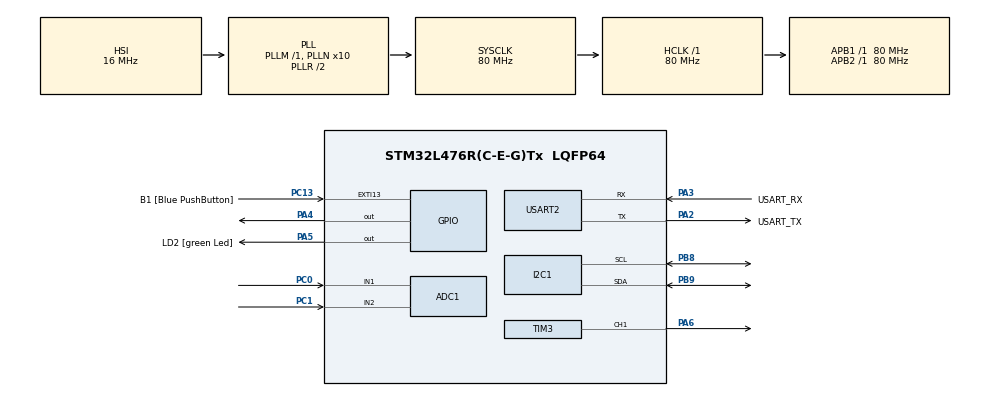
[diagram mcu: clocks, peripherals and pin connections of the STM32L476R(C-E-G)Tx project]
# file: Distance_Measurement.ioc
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ADC1.Channel-0\#ChannelRegularConversion=ADC_CHANNEL_1
ADC1.NbrOfConversionFlag=1
ADC1.OffsetNumber-0\#ChannelRegularConversion=ADC_OFFSET_NONE
ADC1.Rank-0\#ChannelRegularConversion=1
ADC1.SamplingTime-0\#ChannelRegularConversion=ADC_SAMPLETIME_2CYCLES_5
ADC1.master=1
I2C1.Timing=0x10909CEC
Mcu.Family=STM32L4
Mcu.Name=STM32L476R(C-E-G)Tx
Mcu.Package=LQFP64
NVIC.PriorityGroup=NVIC_PRIORITYGROUP_4
PA13\ (JTMS-SWDIO).GPIO_Label=TMS
PA13\ (JTMS-SWDIO).Mode=Serial_Wire
PA13\ (JTMS-SWDIO).Signal=SYS_JTMS-SWDIO
PA14\ (JTCK-SWCLK).GPIO_Label=TCK
PA14\ (JTCK-SWCLK).Mode=Serial_Wire
PA14\ (JTCK-SWCLK).Signal=SYS_JTCK-SWCLK
PA2.GPIO_Label=USART_TX
PA2.GPIO_Mode=GPIO_MODE_AF_PP
PA2.GPIO_PuPd=GPIO_NOPULL
PA2.GPIO_Speed=GPIO_SPEED_FREQ_VERY_HIGH
PA2.Mode=Asynchronous
PA2.Signal=USART2_TX
PA3.GPIO_Label=USART_RX
PA3.GPIO_Mode=GPIO_MODE_AF_PP
PA3.GPIO_PuPd=GPIO_NOPULL
PA3.GPIO_Speed=GPIO_SPEED_FREQ_VERY_HIGH
PA3.Mode=Asynchronous
PA3.Signal=USART2_RX
PA4.Signal=GPIO_Output
PA5.GPIO_Label=LD2 [green Led]
PA5.GPIO_ModeDefaultOutputPP=GPIO_MODE_OUTPUT_PP
PA5.GPIO_PuPd=GPIO_NOPULL
PA5.GPIO_Speed=GPIO_SPEED_FREQ_LOW
PA5.Signal=GPIO_Output
PA6.Signal=S_TIM3_CH1
PB3\ (JTDO-TRACESWO).GPIO_Label=SWO
PB3\ (JTDO-TRACESWO).Signal=SYS_JTDO-SWO
PB8.Mode=I2C
PB8.Signal=I2C1_SCL
PB9.Mode=I2C
PB9.Signal=I2C1_SDA
PC0.Signal=ADCx_IN1
PC1.Signal=ADCx_IN2
PC13.GPIO_Label=B1 [Blue PushButton]
PC13.GPIO_ModeDefaultEXTI=GPIO_MODE_IT_FALLING
PC13.GPIO_PuPd=GPIO_NOPULL
PC13.Signal=GPXTI13
PC14-OSC32_IN\ (PC14).Signal=RCC_OSC32_IN
PC15-OSC32_OUT\ (PC15).Signal=RCC_OSC32_OUT
PH0-OSC_IN\ (PH0).Mode=HSE-External-Oscillator
PH0-OSC_IN\ (PH0).Signal=RCC_OSC_IN
PH1-OSC_OUT\ (PH1).Mode=HSE-External-Oscillator
PH1-OSC_OUT\ (PH1).Signal=RCC_OSC_OUT
ProjectManager.HeapSize=0x200
ProjectManager.StackSize=0x400
ProjectManager.TargetToolchain=STM32CubeIDE
RCC.ADCFreq_Value=64000000
RCC.AHBFreq_Value=80000000
RCC.APB1Freq_Value=80000000
RCC.APB1TimFreq_Value=80000000
RCC.APB2Freq_Value=80000000
RCC.APB2TimFreq_Value=80000000
RCC.CortexFreq_Value=80000000
RCC.HCLKFreq_Value=80000000
RCC.HSE_VALUE=8000000
RCC.HSI_VALUE=16000000
RCC.LSE_VALUE=32768
RCC.MSI_VALUE=4000000
RCC.PLLN=10
RCC.PLLSourceVirtual=RCC_PLLSOURCE_HSI
RCC.PREFETCH_ENABLE=1
RCC.SYSCLKFreq_VALUE=80000000
RCC.SYSCLKSource=RCC_SYSCLKSOURCE_PLLCLK
RCC.USBFreq_Value=64000000
RCC.VCOOutputFreq_Value=160000000
SH.ADCx_IN1.0=ADC1_IN1,IN1-Single-Ended
SH.ADCx_IN2.0=ADC1_IN2,IN2-Single-Ended
SH.S_TIM3_CH1.0=TIM3_CH1,PWM Generation1 CH1
TIM3.AutoReloadPreload=TIM_AUTORELOAD_PRELOAD_ENABLE
TIM3.Channel-PWM\ Generation1\ CH1=TIM_CHANNEL_1
USART2.VirtualMode-Asynchronous=VM_ASYNC
VP_TIM3_VS_ClockSourceINT.Mode=Internal
board=NUCLEO-L476RG

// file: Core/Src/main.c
/* USER CODE BEGIN Header */
/**
  ******************************************************************************
  * @file           : main.c
  * @brief          : Main program body
  ******************************************************************************
  * @attention
  *
  * Copyright (c) 2025 STMicroelectronics.
  * All rights reserved.
  *
  * This software is licensed under terms that can be found in the LICENSE file
  * in the root directory of this software component.
  * If no LICENSE file comes with this software, it is provided AS-IS.
  *
  ******************************************************************************
  */
/* USER CODE END Header */
#include "main.h"

/* USER CODE BEGIN Includes */
#include "stm32l4xx_hal.h"
#include <stdio.h>
#include <stdbool.h>
#include <string.h>
/* USER CODE END Includes */

/* USER CODE BEGIN PD */
#define TMF8801_ADDR ( 0x41 << 1)
#define APPREQID 0x02
#define Bootloader 0x80
#define TMF8x01_OK 0x00  // or whatever the success code is
#define TMF8x01_NK 0x01  // failure or not ready
#define ID 0xE3
#define COMMAND 0x10
#define FACTORY_CALIB 0x0A
#define APPID 0x00
#define DOWNLOAD_CALIB_AND_STATE  0x0B
#define FACTORY_CALIB_0  0x20
#define STATE_DATA_WR_0 0x2E
#define CMD_DATA7 0x08
#define CMD_DATA6 0x09
#define CMD_DATA5 0x0A
#define CMD_DATA4 0x0B
#define CMD_DATA3 0x0C
#define CMD_DATA2 0x0D
#define CMD_DATA1 0x0E
#define CMD_DATA0 0x0F
#define DISTANCE_MEASURE_MODE 0x02
#define STATE_DATA_RD_0  0x2F

/* USER CODE END PD */

ADC_HandleTypeDef hadc1;

I2C_HandleTypeDef hi2c1;

TIM_HandleTypeDef htim3;

UART_HandleTypeDef huart2;

/* USER CODE BEGIN PV */
//uint8_t factory_calib_data[14]={0x41,0x57,0x01,0xFD,0x04,0x00,0x00,0x00,0x00,0x00,0x00,0x00,0x00,0x04};
uint8_t algo_state_data[11]={0xB1,0xA9,0x02,0x00,0x00,0x00,0x00,0x00,0x00,0x00,0x00};
uint8_t factory_calib_data[14];
uint32_t adc_vals[2];
const uint8_t tmf8801_initBuf[] = {
0x10,0x6D,0xC9,0x41,0x85,0x3D,0x15,0xAA,0x51,0xF4,0xD2,0x9E,0xA8,0xA7,0xAC,0x77,0xE9,
0x10,0xF9,0xEC,0x20,0x24,0x63,0xB8,0xF1,0xA5,0x0B,0xA7,0x65,0xB4,0x32,0xB8,0x18,0xD7,
0x10,0x5C,0xF4,0x00,0xD0,0xDC,0xFD,0xD9,0xD5,0x98,0xAF,0x6F,0x40,0x96,0x0A,0xB2,0xFA,
0x10,0x9E,0x13,0x44,0xF8,0x6F,0x5B,0xF1,0x65,0xA6,0x88,0x67,0xD7,0x75,0x0A,0x4A,0x7F,
0x10,0x81,0x9C,0xF6,0x91,0x7B,0xCF,0xF2,0x7C,0x7D,0x84,0xF3,0xA5,0xF6,0xEB,0xD2,0xFA,
0x10,0x59,0x01,0x7B,0x81,0xB2,0xA9,0x31,0x0B,0x8D,0x14,0x9D,0xFE,0xAA,0x24,0x5A,0x5A,
0x10,0x77,0xF0,0x00,0x00,0x88,0x76,0xBA,0x20,0xD1,0x33,0xB2,0x66,0xCF,0xD9,0x37,0xDD,
0x10,0x4C,0xF8,0x5E,0xAD,0x8C,0xF5,0xF4,0x7A,0x60,0x3D,0xFB,0x05,0x4B,0xB9,0x26,0xA5,
0x10,0xDF,0xF1,0xE3,0xC7,0x7E,0x55,0xEC,0x50,0x9C,0xE3,0xC9,0xDA,0x91,0xAE,0x5E,0x9F,
0x10,0x13,0x0E,0x96,0x52,0x27,0x8E,0x06,0x22,0x63,0x69,0xAC,0x61,0x9C,0x23,0xF1,0x38,
0x10,0x5F,0x3A,0x1D,0x03,0xBD,0xCA,0xDA,0x42,0xBB,0x21,0x55,0x35,0xC8,0x30,0x50,0x6D,
0x10,0x09,0xBF,0x32,0x39,0x7D,0xF1,0x4B,0x9C,0x09,0x33,0xF0,0xA1,0xBD,0x1B,0x89,0xCD,
0x10,0xCC,0x75,0x51,0x92,0x52,0x8E,0xA8,0xD1,0xD2,0xED,0x6B,0x63,0x41,0x38,0x0F,0x22,
0x10,0xFF,0xA6,0x6A,0xE3,0xE0,0x78,0x83,0xF5,0x95,0xC2,0x88,0x77,0xE0,0x4B,0x9C,0xAD,
0x10,0x32,0xE4,0x39,0x85,0xBF,0x4E,0x2C,0x21,0xCF,0x19,0x9F,0x93,0xFD,0x9B,0xFA,0x15,
0x10,0x2D,0xB5,0x7C,0xD1,0x43,0x83,0x58,0x4F,0x8C,0x66,0x3E,0xAA,0xD2,0xD2,0x66,0xA1,
0x10,0x56,0x80,0x1A,0xF1,0x65,0x1F,0x4D,0xC5,0x22,0x64,0xB0,0x02,0x7F,0x6A,0x55,0xCE,
0x10,0xA0,0x84,0x62,0x67,0x92,0xE1,0xF9,0x8D,0xE5,0x0F,0x11,0x5B,0x4A,0x4D,0x4A,0xDD,
0x10,0x30,0x5B,0xE7,0x0F,0xDB,0x52,0xD3,0x9A,0xA6,0x0F,0x71,0xD0,0x5C,0x42,0x49,0xFA,
0x10,0xA8,0x9E,0x8B,0x97,0xE2,0x0D,0x13,0xF6,0x92,0x4C,0x97,0xF4,0x29,0x40,0x74,0x44,
0x10,0xE9,0x60,0x0B,0x3F,0xD5,0xD8,0x3B,0x79,0x8F,0x15,0x48,0x82,0x09,0xC5,0x81,0x10,
0x10,0x5B,0xF8,0xE1,0xC7,0x42,0x12,0x1B,0x9A,0x03,0x53,0x41,0x16,0x35,0xC8,0xCB,0x63,
0x10,0xC6,0xB0,0x14,0x84,0xEB,0x29,0x7E,0x5F,0x11,0x41,0x19,0xEF,0xEE,0xD5,0x00,0x8D,
0x10,0xF6,0xC5,0x7C,0x89,0x54,0x24,0xD2,0xBD,0xC1,0xED,0xCE,0x9A,0x88,0xFF,0xE6,0x2D,
0x10,0x57,0x34,0x50,0xCC,0x60,0xC7,0xCF,0x50,0xCC,0x20,0x5B,0x97,0xCC,0x02,0x1B,0x4C,
0x10,0xBF,0x6E,0x1F,0x86,0xC2,0xFB,0x07,0x83,0xCA,0xDE,0x08,0x3A,0xF4,0x99,0xE1,0x3C,
0x10,0x79,0xF5,0xCC,0xFA,0x8F,0x19,0xC8,0x39,0x0F,0x5E,0x7B,0xFA,0x9A,0x99,0xAD,0x7E,
0x10,0x17,0x74,0xF1,0x0C,0x1D,0x8F,0xD8,0x05,0x4A,0xA3,0x06,0x22,0xA8,0x83,0x77,0xDE,
0x10,0x51,0x77,0x4B,0x74,0xD0,0x12,0x60,0x87,0x45,0x61,0xF5,0xBA,0xBD,0x41,0x9B,0x1B,
0x10,0xE5,0xB5,0xFC,0xA9,0x98,0xFC,0x6F,0x29,0x71,0xBB,0x19,0x6E,0xB4,0xC3,0x40,0x28,
0x10,0xB7,0xC7,0x61,0x4D,0xA3,0xB1,0x27,0x3C,0x7F,0x12,0x68,0x69,0xD7,0xF4,0x87,0x1C,
0x10,0x7F,0x41,0x6B,0x3A,0xF8,0x5E,0x95,0x03,0xA5,0x4E,0xB2,0x70,0x4A,0xEC,0xC1,0x10,
0x10,0xE6,0x72,0x1B,0xA7,0x31,0xD1,0x92,0x3C,0x96,0x87,0x7F,0xCF,0x76,0x8A,0xC4,0xDC,
0x10,0x5F,0x69,0x92,0xAE,0xA9,0xF5,0x63,0x9A,0xC4,0x67,0xBA,0x15,0x0B,0xB7,0x76,0xF3,
0x10,0x56,0x65,0x37,0x41,0x85,0x3D,0x85,0xA1,0xC0,0x24,0x09,0x90,0x66,0xFF,0x0B,0xE8,
0x10,0xBD,0x54,0xEF,0x83,0xBE,0xB0,0x6D,0xB8,0xDE,0x30,0x3B,0xF8,0x9A,0xC1,0x1C,0x7F,
0x10,0x2E,0x72,0xC2,0xD7,0xBC,0xD7,0xCA,0xAF,0x97,0x7D,0x5F,0x59,0x68,0x57,0x0B,0x78,
0x10,0x8F,0xD2,0x63,0xC4,0x94,0x3B,0x26,0x4A,0xB9,0x60,0x08,0x69,0x88,0x66,0x91,0xC3,
0x10,0x5C,0xD7,0x77,0xFD,0x46,0x1D,0x3A,0xB3,0x76,0xF7,0x63,0x5E,0x1C,0x84,0x66,0x87,
0x10,0x44,0xFF,0x66,0x07,0xFC,0x51,0xCE,0xAE,0xB8,0xE8,0x44,0x51,0x0D,0x6C,0x79,0xC0,
0x10,0xFC,0xDF,0x57,0x8D,0xDF,0xF4,0x90,0xF5,0xD5,0x01,0xA2,0x1F,0x05,0x70,0x26,0x2F,
0x10,0x30,0xCE,0x07,0x06,0x00,0x57,0xFD,0xCB,0x40,0xA6,0xA8,0xCA,0xE7,0xE0,0x38,0x2F,
0x10,0xC8,0xB7,0x04,0x30,0xBB,0x9D,0x24,0xDB,0x8E,0x8D,0xA4,0xDC,0x9D,0xFB,0xE6,0x51,
0x10,0x5E,0xB7,0x46,0x23,0x57,0x2D,0x76,0x4D,0x0B,0x85,0x04,0x56,0xA0,0x1F,0x3C,0x17,
0x10,0xFB,0x8D,0x9C,0xBF,0x5A,0xEC,0x5A,0x07,0x22,0x7F,0x97,0x6D,0x2B,0xE4,0x5A,0x78,
0x10,0x34,0x3D,0xC1,0xFB,0x60,0xE7,0xF2,0x3C,0x79,0xF0,0x6D,0xB2,0xB7,0x53,0x7B,0x15,
0x10,0x04,0x2F,0x91,0x58,0x05,0x27,0x51,0x42,0x17,0xC3,0x77,0x38,0xEB,0xED,0x65,0x3C,
0x10,0xDF,0x74,0xCE,0xC4,0x1C,0x75,0x9E,0x2D,0x2D,0x19,0xF3,0xB3,0x3A,0x88,0x27,0x25,
0x10,0x28,0xCB,0x58,0xCF,0xCB,0xD8,0xBD,0x89,0xFF,0x04,0xE9,0xB4,0x71,0x12,0xD1,0x3C,
0x10,0xA5,0x79,0xD3,0xCA,0x9C,0xF6,0x3A,0x9C,0xA8,0xE4,0xC2,0x7F,0x3A,0xFB,0xA0,0xCD,
0x10,0xAC,0x8B,0xB3,0xAB,0xAA,0x67,0x70,0xE6,0xD6,0x7B,0x07,0x8F,0xED,0x75,0xA6,0xC9,
0x10,0x96,0xBB,0x74,0xEC,0x3C,0x62,0xC1,0x84,0xF7,0x08,0x1A,0xE4,0x12,0x12,0x46,0x00,
0x10,0xE7,0xB4,0xC9,0xD5,0xF2,0xBD,0x2E,0xED,0x1E,0x1D,0xCC,0xB0,0x01,0xEB,0x10,0xC2,
0x10,0x43,0xBB,0xDD,0x20,0xEB,0xC0,0x4B,0x6F,0x0D,0x38,0x6C,0x6D,0x57,0xDA,0x94,0xCE,
0x10,0x87,0xEE,0x37,0x07,0x7E,0x11,0x7F,0x23,0x0B,0x14,0x56,0x1F,0xB6,0xAC,0xF8,0x2F,
0x10,0x10,0xA7,0x55,0xD7,0xB6,0x76,0x60,0x26,0xD7,0xD9,0x05,0x5C,0xEB,0x3C,0xB3,0x9A,
0x10,0x73,0x70,0xE9,0xCF,0x3F,0x67,0xC7,0x80,0x03,0x4A,0xF3,0x40,0x7F,0x40,0x9C,0x45,
0x10,0x7A,0x43,0x94,0x5F,0xA3,0x14,0x7E,0x01,0x90,0x70,0xD1,0xCB,0xEA,0x08,0xE9,0x8A,
0x10,0x53,0x7C,0x4B,0x3E,0xEC,0xE7,0x68,0x47,0x03,0x85,0xD8,0x92,0x49,0x97,0x08,0xD7,
0x10,0xDB,0x98,0x90,0xF3,0xB8,0x74,0xF2,0xB7,0x7F,0x12,0xF8,0x90,0x2F,0x81,0xCC,0xF2,
0x10,0x7F,0x81,0x88,0xC4,0xC7,0xA2,0x4F,0xA5,0x88,0xF5,0x27,0x36,0x33,0x92,0xBC,0x6C,
0x10,0xA2,0x38,0x55,0x95,0xAE,0x50,0x1E,0xEA,0x2B,0xDA,0x0B,0xED,0x2E,0xF1,0xC1,0x74,
0x10,0x0A,0x99,0x24,0xD4,0x05,0xA9,0xC5,0xB7,0xD8,0x2D,0xD9,0x43,0x5C,0x75,0x2B,0x4C,
0x10,0x39,0x26,0xCE,0x68,0x55,0xBF,0xE4,0xEB,0x11,0xC1,0x96,0xD1,0x91,0xA5,0x82,0x39,
0x10,0x2E,0xFE,0xB2,0x05,0x47,0x56,0x64,0x57,0xCE,0x58,0x55,0x69,0xB1,0x6A,0xF1,0xC1,
0x10,0xC4,0x6D,0x21,0x77,0x38,0xC6,0xEF,0xC3,0x62,0xED,0x00,0x0B,0x74,0xFE,0xC0,0x3F,
0x10,0x4C,0x84,0x13,0x40,0xC0,0xCB,0x14,0x26,0x36,0x9B,0x54,0x21,0xF6,0x7B,0x4E,0x46,
0x10,0xC1,0x1F,0x98,0x22,0xF3,0xF1,0xA2,0x54,0xF9,0x71,0x8E,0xD5,0x1B,0x7A,0xBD,0x51,
0x10,0x7B,0x58,0xAD,0x0D,0x53,0x16,0xD8,0xFA,0xF7,0xB0,0xD0,0x73,0x2A,0x33,0x8F,0x9F,
0x10,0x48,0xA1,0x53,0x0C,0x27,0xCB,0x51,0xE6,0x48,0x1E,0xBB,0x7D,0x7F,0xB7,0x8F,0xF7,
0x10,0x7B,0x94,0xB8,0xBE,0xC6,0x07,0xD8,0xAE,0xBD,0x1B,0xC0,0x3C,0x71,0xBA,0xD0,0x6E,
0x10,0xF3,0x21,0xF4,0x0A,0xE1,0xE2,0xA4,0x41,0x43,0x0B,0xEB,0x80,0x49,0x9C,0xB0,0xC0,
0x10,0xC3,0x94,0x29,0x64,0xF2,0xC3,0x10,0x90,0xF3,0x22,0xD5,0x20,0x04,0x54,0x6E,0x05,
0x10,0x72,0xBE,0x78,0xDD,0x7A,0xBB,0xEC,0xE1,0xC1,0x88,0x7A,0x28,0x57,0x44,0x94,0x63,
0x10,0x19,0x6A,0x2E,0xD8,0x93,0xE5,0x52,0x4F,0xC8,0xD4,0xA8,0xDA,0x11,0x0C,0x85,0xAD,
0x10,0x20,0xBB,0x36,0x45,0x2D,0xDB,0x54,0xD5,0x5A,0xCF,0x93,0xA5,0x12,0x8F,0xE1,0x15,
0x10,0x09,0xBC,0x3F,0xDC,0x21,0xFE,0xF5,0xC8,0x5A,0x42,0x89,0x78,0xFB,0xF2,0x9B,0xB6,
0x10,0x81,0x3F,0x10,0xFB,0x80,0x36,0x58,0x57,0xC6,0xBF,0x43,0x31,0x08,0x81,0x08,0xD8,
0x10,0xF4,0x9B,0x10,0xD8,0xDB,0x45,0xD0,0x97,0x40,0xFD,0xB7,0x5A,0x9E,0x83,0xBF,0xCC,
0x10,0xAC,0x45,0xDB,0xD4,0x8F,0x39,0xD9,0x1A,0x75,0x69,0x8A,0x09,0x23,0x87,0xF7,0x6D,
0x10,0x3E,0xF6,0xDE,0x59,0x51,0x2F,0x94,0xC3,0x7E,0x13,0x2B,0x82,0x16,0x16,0x6F,0x9A,
0x10,0x4B,0xD9,0x05,0xB1,0xCC,0x0E,0x4B,0x70,0xAE,0x9B,0x9F,0xFC,0xC7,0x7B,0x9A,0x0D,
0x10,0xF2,0x0D,0x72,0x1D,0xF2,0x02,0xA8,0x51,0x27,0xAB,0x05,0x96,0xC0,0x31,0x7E,0xF0,
0x10,0x1D,0x5C,0xA3,0x82,0x2C,0x7A,0x65,0xFF,0xDA,0x79,0xB0,0x4A,0xA2,0x3C,0xD2,0xE7,
0x10,0xC5,0x7F,0x58,0x54,0xB8,0x05,0x25,0x40,0x22,0x84,0xA7,0x18,0x4A,0xCA,0x03,0x33,
0x10,0xC9,0x82,0xB5,0xD6,0x55,0x59,0x42,0x6E,0xE4,0x75,0x20,0xFC,0x53,0x1B,0x49,0xFD,
0x10,0xD7,0x56,0x59,0x07,0x90,0xC5,0xE1,0xA7,0x9F,0xAB,0x7F,0x86,0xF8,0x80,0xDC,0xAE,
0x10,0xD9,0x6C,0x79,0x5B,0x4D,0xE4,0x7D,0xB4,0x00,0xEB,0x71,0xD6,0x0D,0x5E,0x20,0xBB,
0x10,0xD2,0xAD,0xA6,0x10,0x50,0x6D,0x5F,0x70,0x30,0x80,0xD8,0xFB,0x41,0x9E,0xF2,0x15,
0x10,0x59,0xC7,0x79,0xB8,0xD1,0xB5,0x51,0xF9,0x4F,0xCC,0x82,0x40,0xBF,0xBC,0x07,0xE6,
0x10,0x32,0x53,0x75,0x66,0x76,0x26,0x5A,0xE4,0x5C,0xCA,0x10,0x70,0x9D,0x39,0xEA,0x80,
0x10,0xF1,0x0E,0x44,0xA3,0xFB,0xC0,0x70,0x5F,0x14,0x7F,0x68,0x35,0xA9,0xD7,0xC3,0x1A,
0x10,0x64,0x1B,0xF9,0x6A,0x96,0xBC,0x9D,0x6A,0xE3,0xFB,0xEC,0x2C,0x56,0xA3,0x5C,0x77,
0x10,0x06,0x52,0x99,0x1A,0xE0,0x28,0xDC,0x57,0x85,0x36,0x97,0xA9,0x27,0xA9,0x65,0x24,
0x10,0xA5,0x2A,0x41,0x0A,0xE2,0xFE,0x29,0x0A,0x2B,0xF0,0xD6,0xF6,0x11,0x33,0x82,0xFE,
0x10,0xE2,0x0F,0xDE,0x77,0x7E,0x7F,0xBC,0xC7,0xA1,0x78,0xAE,0x04,0x19,0x14,0x64,0x94,
0x10,0x17,0x2A,0x46,0x01,0x7F,0xAA,0x98,0xB9,0xAB,0x60,0x2E,0x38,0x7F,0x1A,0xDE,0xA8,
0x10,0x83,0x85,0xD8,0x8D,0xED,0x12,0xED,0x3D,0xC9,0x61,0x71,0xFC,0xEE,0x63,0xE8,0x59,
0x10,0x16,0x79,0x0A,0xA5,0x2D,0xDD,0xF0,0xE7,0x1D,0x90,0x4E,0x2B,0x63,0x7C,0x44,0x4A,
0x10,0x00,0x49,0xBF,0xBD,0xB2,0x05,0x15,0x9D,0xEB,0x63,0x72,0xC1,0xE6,0x60,0x41,0x6F,
0x10,0x53,0xBB,0x9C,0x61,0xCA,0x28,0x96,0x0B,0x05,0x24,0x49,0xFA,0xFF,0xA6,0xEC,0x73,
0x10,0x92,0x39,0xFD,0xEF,0xEA,0xF3,0xA8,0xC0,0x8E,0x33,0xE1,0x4D,0xF3,0x91,0x0C,0xF9,
0x10,0x0A,0x01,0xCC,0xE5,0x35,0x52,0x22,0x90,0xB7,0xF0,0x3F,0x70,0x80,0x85,0x61,0xC8,
0x10,0x17,0xC8,0x14,0x87,0x93,0x9C,0x6B,0x7B,0x71,0x97,0x2F,0x17,0x06,0x4C,0x77,0x90,
0x10,0x18,0xE1,0xA4,0xD0,0x92,0x8E,0x7A,0x88,0x8F,0xB1,0x85,0x55,0x53,0xA5,0xE0,0x59,
0x10,0x49,0xED,0x7C,0xAA,0xBD,0xD6,0x56,0xE5,0xE8,0x9C,0x84,0xC1,0x92,0x66,0xE7,0x36,
0x10,0xCA,0xE3,0x10,0x8C,0xF4,0x6A,0x98,0xE7,0xE4,0x65,0xA1,0x5A,0xB0,0x57,0x18,0x45,
0x10,0x81,0x6A,0x97,0x93,0x5A,0x06,0x05,0x05,0xE6,0x18,0xEC,0x5B,0xF8,0x3B,0x18,0x4A,
0x10,0xB2,0x0E,0x38,0x46,0x73,0xBC,0x3D,0xAE,0xE5,0xB9,0xA1,0x90,0x72,0x52,0xB8,0xDA,
0x10,0x98,0x77,0x30,0x4E,0x81,0xDD,0xE4,0xC3,0xE6,0xB7,0xBF,0x4E,0xE1,0x19,0x07,0xB8,
0x10,0x77,0xF8,0x42,0xDA,0x0F,0x30,0x25,0x7D,0x51,0xC9,0x39,0x01,0x43,0xA3,0xBD,0x6A,
0x10,0xA6,0x73,0x85,0x29,0x7B,0xA8,0x90,0xC0,0x88,0x7A,0xCA,0xE4,0xD5,0xA3,0xFE,0x5B,
0x10,0xFC,0x0B,0xAD,0x13,0xAD,0x72,0xF4,0xF7,0xF4,0x78,0xA0,0xBE,0x64,0x47,0xEE,0xB4,
0x10,0x75,0x8E,0x49,0xB8,0x7C,0xC2,0x6C,0xAC,0xE6,0xAC,0x4D,0xD1,0x01,0x6E,0x41,0x94,
0x10,0xD6,0x63,0x25,0x5A,0x2B,0xF9,0x7D,0xBA,0xCA,0x2D,0x61,0x07,0x8C,0x04,0x40,0x8A,
0x10,0x34,0xB3,0x1C,0x42,0x5C,0x3D,0x06,0x57,0xE5,0xFF,0xE0,0x10,0x5A,0xB3,0x56,0x98,
0x10,0xEC,0xDF,0x8A,0xFB,0xBF,0xB6,0x99,0xFD,0xE0,0xC2,0x73,0x8B,0xE2,0x10,0xE9,0xBF,
0x10,0x7B,0x90,0x18,0x9C,0x6C,0xDE,0x3A,0x3E,0xBE,0xE7,0x80,0xCA,0xF6,0x36,0xE9,0x19,
0x10,0x06,0x3E,0xC5,0x9A,0xC1,0x79,0x72,0x0C,0xF9,0xCE,0x3A,0x5F,0x85,0xDA,0xC2,0x1C,
0x10,0x0B,0x8E,0xF7,0x66,0x7E,0xDC,0x52,0x67,0xB0,0x5F,0x12,0xF0,0x3D,0xE2,0xDD,0x8A,
0x10,0x63,0xDC,0xB6,0x5E,0x02,0x15,0xBB,0x87,0x70,0x52,0xB8,0x2E,0x7B,0xF3,0xA5,0x2F,
0x10,0x78,0xC5,0xD1,0x94,0x97,0x11,0xAE,0xD9,0x46,0x7C,0x1A,0xE3,0xFD,0x63,0x3A,0x14,
0x10,0x96,0xF6,0x59,0x40,0x29,0x9B,0xC3,0x1B,0x96,0x20,0x56,0x30,0x41,0x98,0xEF,0x3F,
0x10,0xB7,0x5A,0x91,0x79,0xD5,0x54,0x97,0x9C,0x99,0x2E,0x49,0x1E,0xA7,0x9C,0xEF,0x7D,
0x10,0xF0,0xB8,0xE5,0x9F,0xC2,0x56,0xE5,0xAA,0xA5,0x9C,0x3E,0x29,0xF8,0xEA,0x5A,0x05,
0x10,0xD9,0x66,0x6D,0xA0,0xF5,0x32,0xB1,0x98,0xCD,0x24,0xCA,0xB7,0x50,0x89,0x2C,0x68,
0x10,0xB9,0xD2,0x55,0x2F,0x76,0x97,0xDC,0xB5,0x64,0x8E,0x5D,0x4F,0xC7,0xCA,0xAD,0x8E,
0x10,0xF9,0xF7,0xE1,0x37,0x48,0xD5,0xD4,0xA7,0x28,0x88,0x63,0x8C,0x72,0x29,0x25,0xEF,
0x10,0x8E,0x49,0x7F,0x80,0x83,0x11,0x62,0x6F,0x5A,0xE8,0x23,0x7B,0x44,0xB8,0xB6,0xBC,
0x10,0x71,0xB4,0x37,0x52,0xD4,0xAF,0x8C,0x5D,0x8A,0xEF,0x1C,0x4F,0x15,0xBB,0xDC,0xEC,
0x10,0x45,0xE2,0x48,0x04,0x59,0x39,0xD1,0xE6,0xF5,0xD6,0x17,0x0D,0x12,0xEB,0xB5,0xA3,
0x10,0xCF,0x25,0x1C,0xFB,0x40,0x72,0x2B,0xE8,0x58,0xF0,0xC0,0x66,0xD7,0x3F,0x3D,0x34,
0x10,0xBA,0xC4,0xE2,0xBE,0x40,0x92,0x7C,0x0D,0x79,0x73,0xBA,0x7C,0x57,0xB9,0xE8,0xC4,
0x10,0x3E,0xCF,0xDF,0x43,0x71,0xD3,0x77,0xBF,0xF2,0xD5,0x73,0xF6,0x3E,0xFA,0x00,0xB0,
0x10,0x77,0x2D,0xAA,0xDF,0xF7,0x61,0xE2,0xE9,0xE0,0x1E,0xA6,0x1E,0xEE,0x5F,0xE6,0x5A,
0x10,0x86,0x18,0x25,0x05,0x9B,0xA3,0x96,0xA8,0xD8,0x59,0xEB,0xAB,0x0D,0xD1,0xE1,0x6A,
0x10,0xB9,0xEC,0x7D,0x5F,0x02,0x70,0x6E,0x0C,0xCB,0x25,0x5C,0x5D,0x68,0xE3,0x4B,0xFE,
0x10,0xA7,0x3C,0x51,0xE2,0xD2,0x77,0x44,0xDA,0xDC,0x24,0x20,0x2F,0x7B,0xC0,0xE3,0x63,
0x10,0x72,0x6B,0xF2,0x1F,0x4B,0x59,0xFF,0x0D,0xFB,0x69,0xF8,0x1F,0xC1,0xF8,0x4D,0x21,
0x10,0xFF,0x6B,0x28,0x60,0x72,0x32,0x08,0xD0,0x1D,0xF8,0xDF,0x25,0x5C,0x05,0xEE,0x39,
0x10,0xEB,0x7E,0xF4,0xBA,0xFA,0xD0,0x83,0x6A,0x81,0x5E,0x53,0x25,0xE1,0x6F,0x3B,0xB7,
0x10,0xA5,0x77,0x5B,0x5C,0x43,0x8E,0xD2,0xC7,0x39,0x84,0x00,0x6D,0xA8,0x0C,0x1C,0xB9,
0x10,0x79,0xDF,0xEE,0xBD,0xC8,0xFA,0xAC,0x6B,0xE3,0x3F,0x4B,0xFB,0x61,0x09,0x04,0x14,
0x10,0x25,0x74,0xA2,0xC4,0xF2,0x42,0x30,0x4C,0x41,0x03,0x91,0x05,0x87,0xD4,0x19,0xA6,
0x10,0xB5,0x17,0x14,0x9E,0xAD,0x62,0xC3,0x46,0x17,0x9A,0x3A,0x9A,0x59,0xC4,0x81,0x25,
0x10,0xB5,0x86,0x82,0x54,0xEA,0x34,0x22,0x88,0x78,0x7D,0xF0,0xDF,0x1D,0x1C,0x78,0xF5,
0x10,0xB6,0x47,0x0E,0x5C,0x21,0x2D,0x41,0xFA,0x61,0x38,0xBD,0xC5,0xE6,0x3B,0xB4,0x60,
0x10,0x1B,0xD7,0xC2,0x0A,0xFE,0x5A,0x1A,0x58,0xBC,0x36,0x6A,0x93,0x2D,0xB1,0xA6,0xA8,
0x10,0xB1,0x7C,0x80,0x28,0xA5,0xF4,0x3A,0x00,0x9A,0x0B,0x80,0x78,0x86,0x96,0x4F,0xDE,
0x10,0xAE,0xF4,0xF6,0x7B,0x41,0x99,0x49,0xC6,0x65,0xC6,0x65,0x7E,0x10,0x22,0x3A,0x54,
0x10,0x0B,0xFD,0x62,0x90,0xC1,0xFE,0x76,0xDF,0x61,0x1F,0x94,0x53,0xB8,0x5A,0xDE,0x9A,
0x10,0x5E,0x2E,0xA2,0x06,0x96,0x5F,0x9C,0xAA,0x27,0x08,0x7A,0x98,0xAD,0x08,0xF0,0xE1,
0x10,0xE1,0xF9,0xDD,0x7C,0xD6,0x7A,0x58,0x91,0xCD,0x62,0x3E,0x8C,0xF2,0xCA,0x05,0x29,
0x10,0x29,0x5D,0x14,0xDD,0xA9,0x2A,0xD2,0x39,0x17,0xA2,0x42,0x69,0x72,0x93,0x51,0x88,
0x10,0x17,0x51,0x7D,0xC6,0x3A,0xD9,0x44,0xF7,0x48,0x63,0xD6,0xCE,0x17,0xFA,0x50,0x7C,
0x10,0x72,0xC1,0xC8,0xD1,0x70,0x5A,0x0E,0x6A,0x0C,0xE2,0xBD,0x96,0xFF,0xEA,0xAF,0xEF,
0x10,0xDF,0x74,0x57,0x35,0x33,0x46,0xA9,0x8B,0x1F,0x02,0x05,0x99,0x76,0x15,0xBA,0x46,
0x10,0xD8,0xDA,0x51,0xA5,0x21,0x92,0x5A,0x47,0x5A,0x2F,0xDA,0x2B,0x82,0x82,0x53,0x11,
0x10,0x93,0xC2,0x50,0x61,0xEC,0x41,0x92,0x84,0xFD,0x63,0x4A,0xA2,0xD8,0x20,0x31,0xCD,
0x10,0xB9,0xB3,0x67,0xD6,0x7A,0xA1,0x13,0x91,0x53,0x4F,0xED,0xF0,0x4B,0x34,0x6C,0x85,
0x10,0x9C,0x54,0xFB,0xE7,0xE8,0x37,0x14,0x2B,0x75,0x9D,0xFA,0xFA,0x35,0x33,0xDE,0x40,
0x10,0xA5,0x3E,0xDB,0xC8,0x5C,0x11,0xEF,0x5C,0xAE,0xDE,0x4C,0xAD,0x9D,0x65,0x48,0x92,
0x10,0x96,0x9F,0x2A,0xA2,0xF9,0x23,0xD6,0x3A,0xD0,0x39,0xEE,0x9D,0xEF,0xA9,0x75,0xAC,
0x10,0xAF,0xC1,0x11,0xCB,0x3F,0xED,0x8C,0x9D,0xAA,0x42,0x28,0xF4,0xC4,0x04,0x52,0x5E,
0x10,0x1E,0x7A,0x6F,0xAA,0xA3,0x78,0xF1,0x8D,0x5A,0x5A,0x76,0x78,0xCE,0x2E,0x5C,0x95,
0x10,0x5A,0x1A,0x0D,0x6B,0x5B,0x15,0x43,0xA3,0x15,0xC2,0x1E,0x43,0xD5,0x7F,0xA9,0xB5,
0x10,0x6F,0xCC,0xB1,0xE7,0x44,0x56,0xED,0x00,0x63,0x43,0x0C,0xF3,0x6A,0xFC,0xE3,0x77,
0x10,0x57,0xEE,0xF9,0x0C,0xB3,0x13,0x64,0x7B,0x26,0xBA,0xCD,0x13,0x3B,0xAE,0x14,0xEC,
0x10,0x89,0x34,0x75,0xAB,0x3E,0x0F,0x32,0x0F,0xDD,0x06,0x05,0x04,0x1A,0xA8,0xEA,0xB4,
0x10,0x6D,0xB4,0x31,0x23,0x12,0x09,0x69,0x8A,0x76,0x90,0x48,0x37,0xF7,0x60,0xF9,0x8D,
0x10,0x84,0x8C,0x74,0xEF,0xAB,0x07,0xF7,0x0F,0x60,0x4F,0xDD,0x09,0x41,0xA2,0xF5,0x6E,
0x10,0xBF,0x8D,0xDA,0xE3,0x85,0x88,0x49,0xD2,0x80,0x02,0x07,0x93,0xE6,0x91,0xC9,0xAA,
0x10,0x1F,0x8D,0x36,0x42,0x37,0xF8,0x2A,0x3B,0x0F,0x25,0x0B,0x09,0x62,0x13,0xF5,0xEE,
0x10,0x1A,0x28,0xC3,0x47,0xBC,0x8D,0xC5,0x6E,0x7B,0xD2,0x0D,0xDB,0xB9,0xB2,0xB4,0xB1,
0x10,0x7F,0x1E,0x42,0xE7,0x39,0xAC,0xEA,0xA6,0x43,0x10,0xCD,0xF2,0xA3,0xFE,0xCE,0x11,
0x10,0x31,0x2F,0xF0,0x09,0x96,0x27,0x70,0x17,0xAC,0xA3,0x77,0xF6,0xE1,0xFE,0xE7,0xB3,
0x10,0x7B,0xD1,0x54,0xBC,0x44,0x89,0x4A,0xF9,0x98,0x3D,0x38,0xCC,0xC2,0xB2,0xFF,0x66,
0x10,0x5F,0xEF,0x55,0xB6,0x5F,0x07,0xB1,0xDF,0x7C,0x06,0x36,0x03,0xFA,0xC3,0xFC,0x85,
0x10,0x5B,0x0A,0x35,0x27,0x23,0xBE,0x93,0x09,0x4A,0xC4,0x3E,0x47,0xF5,0x52,0x99,0x4D,
0x10,0x34,0xB2,0x2E,0x75,0x94,0x19,0x26,0x47,0xE1,0xE3,0x08,0xC4,0xC1,0xF0,0x23,0x4B,
0x10,0x60,0x0D,0xF1,0xB6,0x75,0x03,0x56,0x10,0x20,0xF4,0x1E,0x0B,0x82,0xA5,0x17,0x22,
0x10,0xB9,0x53,0xEA,0x26,0x49,0x84,0xC5,0xFC,0x0E,0xEC,0xFF,0x0B,0xED,0xA7,0x3C,0x25,
0x10,0x9C,0x36,0x90,0xAA,0x7F,0x49,0x28,0x8D,0x4D,0xA0,0xF4,0xF9,0x0A,0xF1,0x0D,0x4A,
0x10,0x7B,0x8C,0x3F,0x2D,0xCE,0x1A,0xA1,0x9E,0x00,0x12,0x07,0xB1,0x60,0xB9,0x74,0xF6,
0x10,0xE1,0x51,0xE3,0x0A,0x9D,0xB7,0x7F,0xE0,0xFF,0xFA,0x05,0x3C,0xBD,0x2C,0x0C,0xDF,
0x10,0xFF,0xA4,0x25,0xF4,0x23,0x2F,0x8E,0x1D,0xF8,0xD0,0x49,0x56,0x54,0xD4,0x6B,0xCA,
0x10,0xF5,0x1C,0xFF,0xAB,0x0E,0x60,0x94,0x93,0x5B,0xFE,0xDB,0x01,0x5C,0x68,0x52,0x27,
0x10,0xE8,0x3A,0x50,0xB0,0x6F,0xDB,0x70,0x5E,0xC8,0xB0,0x94,0x29,0x66,0xF1,0xDD,0x34,
0x10,0x53,0xCD,0xE0,0xC7,0x3D,0xF1,0x9D,0xDC,0x09,0x71,0x7C,0xBF,0x5C,0x44,0x9F,0x72,
0x10,0x4B,0xE9,0xC8,0x9D,0x17,0xF4,0x2F,0x06,0x04,0xEB,0x06,0x86,0x17,0x72,0x69,0xF6,
0x10,0x3B,0xC2,0x1F,0x96,0xF3,0xF7,0xD1,0xD1,0x1A,0x97,0x79,0x9B,0xDC,0xFF,0x09,0xBF,
0x10,0x18,0xDE,0xEA,0x60,0x02,0x3D,0xA8,0xED,0x57,0x89,0x86,0x46,0x00,0x88,0x9B,0xDC,
0x10,0x3E,0x85,0x88,0x21,0xC2,0x10,0x64,0x41,0x62,0xD4,0x05,0x0B,0x88,0x09,0x75,0xC8,
0x10,0x73,0x07,0x42,0x26,0x91,0x8B,0x5F,0x7C,0xDE,0xC1,0x4A,0x00,0x81,0x80,0x69,0xBA,
0x10,0x6A,0x19,0xBD,0x04,0x43,0xF4,0xA2,0x1B,0x78,0x17,0x1F,0x8A,0x7D,0x8A,0x5D,0x69,
0x10,0xDD,0xA8,0xE3,0x91,0x5B,0x27,0xE6,0x2F,0x65,0xDE,0x7C,0x53,0x62,0x61,0x02,0x6E,
0x10,0x22,0x36,0x7D,0x99,0xAB,0xDB,0x65,0xC7,0x7F,0xB6,0x2A,0x8C,0x90,0x3B,0x3C,0xB6,
0x10,0x1C,0xBA,0xD2,0x99,0xB3,0x50,0xB5,0x9E,0xB3,0x5D,0xF0,0xB4,0x69,0x2A,0xFA,0x86,
0x10,0x06,0xB5,0x3F,0xF6,0x03,0x3B,0xE2,0xEA,0xA9,0x63,0x62,0x06,0x63,0x58,0xF1,0xF2,
0x10,0x25,0x3C,0x97,0x43,0x2C,0xEE,0xEF,0xC9,0x2A,0xF0,0x7F,0x90,0x70,0xCA,0x4C,0x4C,
0x10,0xAD,0xA8,0xDE,0xEB,0x05,0x28,0x03,0x2B,0xED,0x74,0xDA,0x17,0x96,0xCB,0x02,0x60,
0x10,0x02,0x62,0x5A,0xE3,0x15,0xEE,0x9B,0xFE,0x4B,0xF7,0x21,0xBD,0x66,0xEA,0x1A,0x0C,
0x10,0x1B,0x8E,0xE8,0x20,0xBC,0xD1,0xFC,0x29,0x47,0x49,0x5B,0x4A,0xC7,0xBB,0x28,0xAD,
0x10,0xFC,0x06,0xD0,0x63,0x18,0xAC,0x79,0x77,0x5D,0x30,0x7E,0x91,0x8D,0x4A,0x99,0x27,
0x10,0x0C,0xCB,0xA5,0x79,0xAC,0x5E,0xD8,0x3B,0x12,0x30,0xED,0xE9,0x6C,0x6F,0x39,0x6D,
0x10,0x96,0x30,0x4B,0xDF,0x03,0xF9,0x6D,0xFD,0xE7,0xEE,0x82,0x79,0x8C,0xF2,0xC4,0x67,
0x10,0x0D,0x86,0x79,0xB6,0xCC,0xA9,0x72,0xEF,0xB5,0x06,0x2C,0xC0,0xFF,0xAA,0x81,0x91,
0x10,0x42,0xD7,0xF3,0xCA,0x83,0xA4,0x15,0x63,0x54,0x47,0xD7,0x8B,0xEA,0x18,0x45,0x56,
0x10,0xA1,0x2F,0xAF,0xCF,0x5C,0x6F,0x42,0x4F,0x9D,0x53,0xAD,0xB3,0x6E,0x78,0x85,0xDD,
0x10,0x30,0x3C,0xAB,0x05,0x0E,0x74,0xF8,0x5B,0x02,0x43,0x4E,0xD7,0xC4,0x73,0xB6,0xB8,
0x10,0xDE,0x9B,0xAB,0x6F,0x05,0x9E,0x52,0x3E,0x07,0x6F,0xAC,0x2A,0x0F,0x4A,0x9E,0xC8,
0x10,0x17,0x24,0xBF,0x8E,0x4B,0xCB,0xB1,0xA0,0xD0,0xAE,0xEE,0x4E,0x6E,0x10,0x09,0xDC,
0x10,0xB5,0xDA,0x78,0xF1,0xE2,0xEE,0xF0,0x3D,0xDB,0x1A,0x4C,0x2D,0x89,0xBB,0xB6,0x50,
0x10,0xBE,0x75,0x70,0x17,0x2A,0x51,0xDB,0xAA,0x53,0x1E,0x30,0x7F,0x78,0x6C,0x7A,0xFF,
0x10,0x07,0x18,0xCB,0x32,0xCA,0x1C,0xDA,0x0D,0x5E,0xA1,0x7A,0xE6,0xF6,0xE7,0xAE,0x41,
0x10,0x36,0x88,0xEB,0xAF,0x24,0x17,0xFE,0xF9,0xDC,0xA6,0xBB,0x79,0xEB,0x8E,0x30,0x62,
0x10,0x8C,0xCB,0x58,0x28,0x5C,0x2E,0xE8,0xD1,0x8B,0x28,0x8D,0xF4,0xF8,0x39,0x75,0x63,
0x10,0x4F,0x4C,0x47,0x3F,0x9B,0x5D,0x16,0x98,0xB7,0xDB,0xBD,0xEF,0xA2,0x0F,0xA6,0x83,
0x10,0x1D,0x1A,0xD1,0xE6,0x64,0xDA,0xF5,0xEF,0x4D,0xAD,0x36,0x6E,0x6E,0x83,0xD9,0x46,
0x10,0x3C,0x62,0x8E,0x6D,0xA5,0x25,0xCB,0xCB,0x73,0x33,0x6F,0x0D,0xE5,0xEA,0xDC,0xE8,
0x10,0x92,0x81,0xC6,0x7C,0xBD,0x4F,0x5A,0xC3,0x23,0x19,0xE8,0x3D,0x16,0x28,0x98,0x16,
0x10,0xF8,0x95,0xC9,0xE3,0xA6,0xA9,0x43,0x08,0x19,0x80,0x44,0xE6,0x63,0xC6,0x3A,0xA2,
0x10,0xBA,0xC5,0xA7,0x9D,0x90,0xB8,0x5E,0xA8,0x00,0xA1,0xD2,0x68,0xCB,0xD2,0x70,0x67,
0x10,0x5F,0xB8,0x79,0x57,0x78,0xC7,0x95,0x58,0x64,0x21,0xEB,0x83,0xA7,0x3E,0xC8,0x0C,
0x10,0x8D,0x8E,0xC8,0xA8,0x34,0xCE,0x1F,0xB4,0x75,0x76,0x06,0x12,0x9E,0x2A,0x4A,0x76,
0x10,0xA5,0x0E,0xEE,0x43,0xD0,0x52,0xDD,0xE2,0xDD,0xE9,0xC4,0xB3,0x79,0xA5,0xB8,0xCC,
0x10,0x9B,0x4A,0x3A,0x31,0x99,0xD6,0xA4,0xB9,0x0D,0x8F,0xC7,0xB3,0x71,0x3C,0xA1,0xEA,
0x10,0x46,0xD7,0xF2,0xD4,0xBD,0xAB,0x98,0x41,0x70,0x01,0xFF,0x75,0xE8,0xBC,0x4C,0xFE,
0x10,0xE2,0xEA,0xC3,0x1A,0xA8,0x6D,0xC0,0xA2,0x43,0x7B,0xAE,0x94,0x1D,0x39,0x64,0x29,
0x10,0xE6,0xB9,0x28,0x13,0x82,0xDF,0x64,0x5D,0xF8,0xCD,0xED,0x4A,0x17,0xAD,0x03,0xB6,
0x10,0xF4,0xB8,0x7D,0xC9,0xE2,0x58,0xE5,0xFD,0x85,0x42,0xE9,0x83,0x99,0x39,0x6A,0x67,
0x10,0x59,0xF3,0xCE,0xDE,0xC9,0x2E,0xFA,0x07,0xB2,0x10,0x45,0xB2,0x65,0xAE,0xB7,0x15,
0x10,0x9C,0xDF,0x86,0x4B,0xEB,0x86,0x32,0x69,0x5A,0x4D,0x23,0x23,0x61,0x48,0xF8,0xBA,
0x10,0x11,0xDE,0xE3,0xDC,0x75,0xF4,0x2E,0xEB,0xD9,0x36,0x8E,0xE2,0xC3,0xCC,0x4E,0xC2,
0x10,0xF1,0x56,0x39,0x63,0x6F,0x22,0x03,0xA1,0xF1,0x2F,0x24,0x74,0xD3,0x35,0x72,0x0E,
0x10,0xF9,0x90,0xD7,0x36,0xBE,0x40,0x88,0x0A,0x22,0x31,0x7A,0x7F,0xFB,0xF5,0x32,0x93,
0x10,0x40,0xCA,0x63,0x43,0x46,0x9D,0x7B,0x80,0xB5,0x41,0xCE,0xD5,0xFC,0x53,0x01,0x3F,
0x10,0xAD,0x96,0x58,0xCC,0x44,0xF5,0x73,0xE6,0xC4,0x30,0xAE,0x93,0xB4,0xD7,0xDC,0xCE,
0x10,0xED,0x92,0x67,0x1F,0x78,0x70,0xC4,0x27,0xAC,0xCB,0xDF,0x93,0xE8,0x5A,0x06,0xAD,
0x10,0xC9,0xDE,0x12,0xF0,0xAE,0x25,0xA7,0xF4,0x40,0x72,0xBF,0x55,0xA8,0x05,0x00,0x56,
0x10,0x51,0x39,0x9E,0x98,0xD3,0x14,0x83,0xF7,0x86,0xD3,0xD2,0xC7,0x5E,0x9A,0xA5,0x16,
0x10,0xED,0xAB,0xB2,0xD1,0xF8,0x8F,0xC0,0x34,0xDD,0x2F,0x7D,0x0D,0xC0,0xB3,0xDA,0x9C,
0x10,0xEB,0x39,0xDA,0xEF,0x4D,0xFD,0xC2,0x04,0x07,0x94,0x6F,0x9F,0x03,0x2B,0x64,0xE5,
0x10,0xEE,0xAF,0x9C,0xC7,0x30,0xC9,0x73,0xAC,0xD9,0x86,0x6E,0x5D,0xA1,0x65,0xF6,0xE4,
0x10,0xCF,0x07,0xAF,0xEB,0xF2,0x3A,0xC5,0xC5,0x8D,0xFA,0xF2,0x5E,0x93,0x0D,0xFB,0xD3,
0x10,0x10,0xBE,0x29,0x8C,0x6D,0x5D,0x73,0x42,0xD8,0x0C,0x89,0xDE,0xAA,0x2A,0x4E,0xE4,
0x10,0x82,0xBE,0xDA,0x54,0x64,0x4F,0x2A,0x80,0x76,0xD9,0x1C,0x5D,0xBF,0x30,0x53,0x67,
0x10,0x72,0xF1,0x5A,0xFD,0xC8,0x2E,0x7D,0xE5,0x10,0xC0,0x54,0xA9,0x97,0xFA,0xB7,0x0F,
0x10,0xF9,0xC8,0x6A,0xF7,0x60,0x44,0x6E,0x5A,0x04,0x35,0xD1,0x06,0xE9,0xE0,0x3B,0x53,
0x10,0x22,0xAF,0x7B,0xB6,0x66,0x09,0x58,0xE2,0x3C,0x2F,0x2B,0xDC,0x9A,0x1C,0xC7,0xEC,
0x10,0xD0,0x14,0x80,0x00,0x8D,0x8F,0x22,0x2F,0xEB,0xD5,0x1A,0xC1,0x17,0x5D,0x83,0x45,
0x10,0x4D,0x59,0x7E,0xBD,0x83,0xB1,0xF4,0x1E,0x92,0x18,0x4D,0xD0,0xB9,0x87,0xAC,0x2B,
0x10,0x52,0xAF,0xA8,0x7C,0xBC,0xD7,0xB8,0xED,0x48,0xF2,0x85,0xE4,0x18,0x14,0x85,0x24,
0x10,0x11,0x3E,0x44,0xED,0xCF,0x3C,0x7A,0x7D,0x73,0x2D,0x61,0x00,0x73,0x9A,0x01,0x46,
0x10,0x63,0xBF,0x77,0x9D,0x97,0x2D,0x0B,0x7F,0xEF,0xF2,0xDB,0x54,0x56,0xEF,0x16,0xA2,
0x10,0x4D,0x9A,0xFF,0x91,0xF5,0xDD,0x84,0x24,0x8C,0x70,0x2C,0x77,0x9E,0xA0,0x92,0xE8,
0x10,0x6F,0x51,0xD7,0x19,0xB4,0x5B,0xDF,0x03,0x49,0x8C,0x38,0x28,0xFB,0xC0,0xE3,0x57,
0x10,0x1A,0xB6,0x44,0xB4,0x12,0xD9,0xEB,0x96,0x89,0xAC,0xCD,0x0B,0x21,0x7E,0x00,0x12,
0x10,0x77,0x4A,0x5E,0xE6,0xF0,0x17,0xB1,0x62,0x44,0x93,0x7B,0xDC,0x04,0x10,0x20,0x0E,
0x10,0xB1,0xE3,0x39,0xF3,0x0B,0x88,0x36,0x3F,0x48,0x87,0xB2,0xFE,0x0A,0xE9,0xE2,0x8F,
0x10,0x17,0xB0,0xB2,0x7A,0x59,0x9B,0x9A,0x8D,0xA5,0xB1,0xDD,0x78,0x65,0x65,0x16,0x6E,
0x10,0x9A,0x04,0x0E,0x71,0x36,0x96,0x74,0xB1,0x29,0x8C,0x31,0x45,0xF9,0xA3,0x70,0x47,
0x10,0xD7,0x5A,0x18,0x80,0x3F,0x70,0x2F,0x29,0x55,0xD0,0x1D,0x31,0x9A,0xD5,0xD7,0x57,
0x10,0xEC,0x5E,0x9C,0xE0,0x4A,0x94,0x51,0xF1,0xFD,0x3A,0x3E,0x93,0x1F,0x1B,0x14,0x71,
0x10,0xBB,0xA6,0x6C,0x7F,0x4E,0x1E,0x0B,0x1A,0x4D,0xB3,0xD0,0xF8,0xB7,0x4F,0x91,0x93,
0x10,0xEE,0x8D,0x7A,0xF5,0x53,0xC5,0xC6,0xD6,0xD8,0x7E,0x64,0x14,0x9F,0xAD,0xC5,0xC9,
0x10,0x19,0xDD,0x12,0x77,0x30,0x31,0x28,0x7B,0x1D,0xEF,0x3F,0x5B,0xA4,0x76,0x1E,0x9B,
0x10,0x7D,0x61,0xDB,0x79,0xF3,0x8D,0x75,0x81,0xED,0x57,0xAD,0x1F,0x29,0x47,0x2F,0xA1,
0x10,0x30,0x5D,0x17,0x68,0xE7,0x3A,0x9B,0x1C,0xDF,0x08,0xA2,0xEA,0x8E,0x61,0x75,0xC3,
0x10,0x70,0xAF,0x50,0x66,0xB2,0xC9,0xEB,0x23,0x72,0x48,0x3A,0x66,0xA6,0x4B,0x60,0x38,
0x10,0x5A,0xF8,0x4A,0x2B,0xDC,0x8E,0xD8,0x3A,0xE3,0xD1,0xB9,0x15,0x54,0xF4,0x65,0x53,
0x10,0x82,0xCC,0x31,0xD2,0x7E,0x94,0x75,0xB1,0x08,0xC1,0xD5,0x8B,0xA6,0x7D,0xD0,0x03,
0x10,0x8A,0x99,0xC8,0xF8,0xA2,0xBC,0x11,0x33,0x83,0xF4,0x05,0x5D,0x21,0x89,0x01,0x34,
0x10,0xFD,0x02,0xEA,0x9A,0xED,0x11,0x31,0xB9,0x3B,0x86,0x6F,0x01,0x6B,0x8D,0xDA,0x41,
0x10,0x46,0x9E,0x8E,0xDE,0x2C,0x66,0x91,0x15,0xBA,0xC0,0x56,0x55,0x37,0x6D,0x1C,0xD8,
0x10,0x46,0xC7,0x2E,0xB4,0xA5,0x5B,0x75,0xB9,0x4B,0xDF,0x61,0x3F,0xA8,0x94,0xCB,0x7B,
0x10,0x01,0xF6,0x53,0x67,0xBA,0x15,0x9C,0x6D,0xB2,0x97,0xCE,0xDE,0x28,0xCB,0x89,0xBD,
0x10,0xC3,0xE2,0x49,0x3D,0x4D,0xF7,0x49,0x9F,0x8B,0x2A,0x39,0xD6,0xD2,0x15,0xA1,0x3A,
0x10,0xEF,0x4B,0x62,0x13,0xC9,0x5A,0xB7,0x11,0x6A,0xE2,0x4A,0x24,0x79,0x1A,0x4C,0x05,
0x10,0x4B,0xBD,0x76,0x84,0x46,0xD1,0xA9,0x01,0xE7,0xB7,0x45,0xD4,0xC4,0x15,0xC4,0xFA,
0x10,0x6F,0x5E,0xDE,0x66,0x1F,0x49,0x4D,0x6C,0xBE,0x86,0xA0,0x23,0xCC,0xAB,0x45,0xB5,
0x10,0x74,0x1F,0xBA,0xCC,0xF1,0x62,0x3F,0x54,0x36,0x5F,0x3E,0x19,0xE0,0x0D,0xBA,0xBC,
0x10,0xFD,0x3F,0x6A,0x38,0x5F,0x0D,0xCF,0xDC,0x8C,0xA8,0x4F,0x87,0xCE,0x02,0xED,0xD0,
0x10,0x9E,0xF3,0x59,0xDF,0x25,0x17,0x49,0xFE,0xE5,0xB4,0x6E,0x44,0x78,0x39,0xC3,0x3F,
0x10,0x6A,0x4A,0x67,0xE4,0xFA,0xD2,0x7E,0xB9,0xD7,0x70,0xDA,0xC2,0x50,0xA2,0x6E,0x8F,
0x10,0xA5,0x09,0x14,0xC3,0x91,0x79,0xF4,0x8D,0xBA,0x12,0x42,0xE8,0x02,0xCD,0x9D,0x4B,
0x10,0x44,0xE6,0x88,0x93,0x6D,0x72,0xF8,0x05,0xAC,0xF5,0x72,0xB9,0x65,0x72,0xC0,0x43,
0x10,0xEB,0xB7,0x71,0x0D,0x0D,0x71,0xD2,0x12,0x7F,0xC3,0x34,0x77,0x00,0x24,0xDB,0x66,
0x10,0x1B,0x96,0xF9,0x65,0xF6,0x03,0xA5,0x86,0x0C,0xA4,0xF2,0x6B,0x7D,0xCD,0x8E,0xF3,
0x10,0x57,0xDE,0x40,0x62,0xD7,0xC2,0xCC,0x57,0xFB,0x9D,0x64,0x47,0xE5,0x50,0x28,0xEF,
0x10,0x18,0x0B,0x80,0x4A,0x42,0x3D,0x82,0xCF,0xF2,0x74,0xED,0x44,0x77,0x5D,0x18,0x5A,
0x10,0x81,0x75,0x03,0x82,0x91,0x7E,0xF6,0x84,0x79,0x70,0x09,0x2D,0x1A,0x36,0x33,0xDD,
0x10,0xBF,0x9E,0xF1,0x90,0x36,0x42,0x8B,0x79,0x44,0x67,0x99,0x13,0x11,0xC0,0x04,0xE4,
0x10,0x8E,0x55,0xE8,0x18,0x8E,0x92,0xAE,0xB6,0x3E,0x40,0x04,0x07,0xFE,0x2E,0x57,0xDC,
0x10,0xB6,0xB7,0xB1,0x8F,0x47,0x72,0xCE,0xCE,0x29,0x47,0x2F,0x39,0xFB,0x98,0x1F,0x40,
0x10,0x3A,0xBF,0x2E,0x31,0x03,0x89,0xCD,0x0E,0xAD,0x39,0x04,0xA7,0xE2,0x4B,0xB1,0x76,
0x10,0x61,0x2E,0x90,0xA0,0xA4,0x3C,0xC8,0xCE,0x7C,0x6C,0xD4,0xB4,0xF6,0xC9,0x51,0xBC,
0x10,0x07,0x40,0xEA,0xC1,0x11,0x8D,0x47,0x9C,0x0F,0xB5,0xF3,0x9D,0xB9,0xFE,0x2A,0xCF,
0x10,0x3E,0x2F,0x85,0xD7,0x4E,0xAF,0xF7,0x60,0xA9,0x90,0x41,0xB0,0x35,0x79,0x60,0xF8,
0x10,0xC7,0xD9,0x09,0xD7,0xF6,0xCC,0xF4,0xD0,0xE9,0xB1,0x4E,0x5C,0xFF,0xD0,0xE8,0x16,
0x10,0x22,0xAB,0x63,0x39,0x67,0xCC,0xB9,0x54,0xA2,0xF4,0xF1,0xCE,0xCE,0xE9,0xC0,0xC0,
0x10,0x0B,0x3B,0x40,0x3A,0x50,0x08,0x63,0x91,0x8C,0x67,0x93,0x28,0x57,0x35,0xF0,0x1C,
0x10,0xF9,0x56,0xD4,0x75,0xB5,0x1D,0x6F,0xB3,0x62,0x88,0x3A,0x4C,0x19,0x5A,0xAD,0x2E,
0x10,0x7E,0x9D,0xEB,0xCF,0x55,0xE9,0x7E,0xCA,0xDE,0xDE,0xB2,0xCB,0x22,0x8F,0x36,0xD0,
0x10,0x18,0x04,0x17,0x9E,0x4C,0x1E,0x4C,0xC4,0x8D,0x0B,0x33,0xAF,0xAC,0x9A,0x5A,0x51,
0x10,0xDA,0xF9,0x09,0x4E,0xC1,0x9C,0x79,0x3E,0x06,0xB7,0x53,0xE0,0x7A,0xAD,0x2E,0xA3,
0x10,0xE0,0x39,0x15,0x7E,0x7D,0x4A,0x27,0x51,0x79,0x61,0xCE,0xEB,0xFA,0x07,0xC8,0x88,
0x10,0x10,0xDE,0xE3,0x80,0x5A,0xC2,0xC4,0x50,0x4F,0x7B,0x42,0x54,0xF2,0xB7,0x3F,0x4B,
0x10,0xE9,0xCB,0x44,0x36,0x69,0xCD,0xDC,0xE0,0xDC,0x33,0x9B,0x0D,0x28,0x63,0x13,0x6E,
0x10,0x26,0x68,0xD8,0x6D,0xF5,0x9C,0x83,0x8B,0x15,0xFF,0x24,0x62,0x89,0x9D,0xDC,0x2E,
0x10,0x11,0x9B,0xD7,0x1E,0x90,0x9D,0x04,0x24,0x51,0x99,0xF1,0xAB,0xD0,0xDF,0x90,0x84,
0x10,0xA5,0x43,0xEE,0xA9,0x71,0x89,0x0D,0x50,0x78,0xA7,0xDC,0x9B,0xDF,0x4B,0xC5,0x3D,
0x10,0x63,0x01,0x2E,0x40,0x73,0x1C,0xA5,0xBC,0x7D,0x2B,0x24,0x0C,0x95,0xFA,0x9E,0x22,
0x10,0xF2,0xD4,0x5E,0xA8,0xAE,0xFC,0xE0,0xBA,0xE3,0xA6,0x06,0x88,0xD1,0xDA,0x5E,0x54,
0x10,0xBE,0x89,0xD5,0x07,0xEF,0x2B,0x34,0x83,0x6D,0x65,0xC0,0xC2,0x83,0xEE,0x8B,0xD8,
0x10,0xDB,0x0F,0x57,0x39,0xE3,0xC2,0xFE,0x53,0xBA,0xBF,0x83,0x2D,0xE7,0x8D,0x5B,0xF6,
0x10,0xA4,0x3C,0x7E,0x96,0x80,0xEE,0x80,0xB0,0x01,0x5F,0xEE,0xFC,0xA3,0xAB,0xD2,0xD6,
0x10,0x8E,0x90,0xC6,0xD6,0x07,0x08,0xD5,0xAC,0x54,0xDA,0x4C,0xD4,0x7D,0xB8,0xB0,0xF5,
0x10,0xA4,0x43,0x41,0xDF,0x28,0xE1,0x52,0x90,0xA7,0x72,0xCD,0x9D,0xB6,0xA1,0x55,0x5D,
0x10,0x7C,0xE9,0x83,0x5B,0xFA,0xD5,0x8A,0x59,0x68,0x7C,0x9D,0xF6,0x99,0xF8,0xC7,0x5F,
0x10,0xEB,0x44,0xC0,0xCA,0xE7,0x69,0x74,0x46,0xF1,0x76,0xDA,0x3F,0x8C,0xE4,0x06,0x06,
0x10,0x12,0xBA,0x29,0xDE,0x4A,0xE9,0x12,0x08,0xC7,0xF7,0x6E,0x00,0xA0,0x1D,0x3C,0x40,
0x10,0xFB,0x46,0xE1,0xCC,0x5D,0x46,0x83,0x84,0xD6,0xF5,0xC8,0x5F,0xD4,0xBE,0x83,0xC9,
0x10,0x03,0x2D,0x85,0x43,0xB1,0xCA,0xF7,0x66,0xAA,0xA2,0x6F,0xDB,0x3E,0x6F,0x5B,0xD0,
0x10,0xEE,0xF2,0xC9,0x78,0x4F,0xA9,0x6B,0x2E,0xA4,0xA6,0x68,0x77,0xC8,0x67,0xDD,0x84,
0x10,0xFC,0x17,0xAE,0x8F,0x1F,0xF1,0x1E,0x1C,0xB7,0xB4,0x53,0x17,0xC2,0x0C,0xF9,0x69,
0x10,0x9F,0x58,0xEA,0x1B,0x32,0x4E,0x88,0xA3,0x29,0x7F,0x77,0x57,0xF4,0x58,0xC6,0x2D,
0x10,0x6E,0x22,0x84,0x86,0xD2,0xB6,0xF8,0xC8,0x7E,0x81,0x52,0x19,0x62,0x46,0x00,0x47,
0x10,0x45,0xC5,0xEC,0x5F,0x5B,0xEF,0xA2,0xF7,0xC4,0x83,0x52,0x97,0x0E,0x4A,0xA3,0x4E,
0x10,0x80,0x24,0xE3,0x3B,0xB3,0x05,0xF1,0xDA,0x84,0x92,0x6D,0x77,0x8D,0xFB,0x38,0x38,
0x10,0x0F,0x0A,0xE4,0xD6,0xF9,0x6C,0x48,0x27,0xD1,0x4A,0xA9,0x22,0xC9,0xA5,0xC3,0x4D,
0x10,0xE6,0xB6,0x1E,0x2C,0x8A,0x5C,0x12,0x23,0x67,0x38,0x86,0x95,0xBF,0x2B,0x40,0x6B,
0x10,0xC9,0x89,0x0A,0xBE,0xBD,0x82,0xDC,0x92,0xFC,0xA2,0xF8,0xB8,0x75,0x87,0x51,0xA2,
0x10,0x25,0x82,0x75,0x28,0x8D,0xFD,0x83,0x73,0xBE,0x29,0x71,0xAC,0xCA,0xC2,0x32,0xD7,
0x10,0xD0,0x4B,0x66,0x30,0xC9,0x92,0xCF,0x1F,0x72,0x42,0xB5,0x64,0x7F,0xFF,0x03,0x12,
0x10,0x93,0x98,0x96,0x32,0x4E,0xF1,0x13,0x70,0x5A,0x34,0xEE,0xF4,0xDF,0x12,0xDF,0x37,
0x10,0x36,0xEB,0x00,0x4B,0xBA,0xA2,0xFC,0x55,0x69,0x97,0x1E,0xB2,0x4E,0x37,0xF9,0x5C,
0x10,0xD0,0x4E,0x0D,0x5F,0x1B,0x2E,0x18,0x27,0x19,0x7A,0x7F,0xFB,0x7E,0xCF,0xDA,0x90,
0x10,0x44,0xEC,0xC9,0xCA,0xBE,0x8E,0x06,0x06,0x91,0x2C,0x58,0xE9,0x7C,0x42,0x80,0xC4,
0x10,0xBA,0xC8,0x6A,0x46,0x64,0x17,0xDE,0xE0,0x6F,0xBF,0x5F,0xD1,0xC6,0x34,0x20,0x31,
0x10,0x9F,0x69,0x30,0x46,0xCA,0x8B,0xC5,0xE4,0x05,0x04,0x0A,0x7D,0xC7,0x37,0xCB,0x2C,
0x10,0x8F,0x62,0x58,0xC3,0xE1,0x52,0xF6,0xF4,0x62,0xCD,0x4D,0x77,0x95,0xE5,0x8E,0xFD,
0x10,0x15,0xF8,0x89,0x79,0xBE,0x88,0x2C,0x2E,0xE1,0xA6,0xE4,0xC5,0xE3,0xB3,0x35,0xEC,
0x10,0x5B,0x0C,0x7A,0xFF,0x76,0xA5,0xE5,0xF6,0xB3,0x9A,0xE9,0x1B,0x31,0x00,0x6C,0x80,
0x10,0x72,0x49,0xAB,0x01,0xBB,0xE5,0xC2,0xFC,0xFE,0x48,0x57,0x98,0xC2,0xCF,0xB1,0xF1,
0x10,0x2D,0x22,0x7B,0xB7,0x8B,0x3B,0x67,0xE6,0x7E,0x1A,0xA3,0x71,0xE6,0x40,0x14,0xA9,
0x10,0x66,0x4B,0xFE,0xD8,0x7F,0xEE,0x98,0xE7,0x5B,0xAE,0x5F,0x9D,0x90,0x7D,0x3D,0x2A,
0x10,0x4B,0x64,0xF5,0x57,0xE5,0x14,0x4B,0x99,0x4B,0xF2,0x64,0x4C,0x74,0xDE,0xC0,0x7C,
0x10,0x88,0xAC,0x9C,0x22,0x21,0xD3,0xDA,0x2D,0xF2,0xC0,0x8E,0x6A,0xA6,0xA8,0x94,0x38,
0x10,0xAA,0x16,0x92,0x2B,0x79,0xB8,0x48,0x60,0xF5,0xDE,0x5E,0x23,0xFF,0x40,0x58,0x28,
0x10,0x05,0x4A,0x86,0xEE,0x57,0x20,0x1F,0xDD,0x02,0x6B,0xFF,0x7F,0xD8,0xE9,0xF9,0x4A,
0x10,0x9B,0x21,0x87,0x7D,0x10,0xE2,0xED,0x70,0xC9,0x59,0xE1,0x58,0xBD,0xE8,0x1E,0xF7,
0x10,0xC2,0xAA,0xC2,0x10,0x7A,0xF6,0x0A,0x31,0x15,0xBD,0x5B,0x36,0xA7,0xE6,0xC0,0xCA,
0x10,0xA7,0xEE,0xD4,0xFC,0x6C,0xA9,0x76,0x88,0xFD,0xFD,0x8D,0xEB,0x23,0x52,0x96,0x98,
0x10,0xF7,0x14,0x83,0x86,0xC8,0x2C,0x2A,0xCC,0x33,0x33,0xEE,0x3A,0xCA,0x22,0xE7,0x86,
0x10,0x11,0xB2,0x46,0xE0,0x30,0x92,0x73,0x95,0x22,0x32,0xB8,0x51,0x83,0xF0,0xE6,0xCE,
0x10,0xBA,0xD9,0x34,0x91,0x2E,0x14,0x64,0x81,0x6F,0x64,0x2D,0x3A,0x9D,0xA8,0x4A,0x17,
0x10,0xA6,0x0E,0x65,0x3F,0xFE,0x82,0x79,0x84,0x45,0xFD,0xF2,0x26,0x66,0xB3,0x9F,0x1E,
0x10,0xFA,0x70,0x1D,0xF2,0xD8,0xE1,0xB1,0xAE,0x5A,0x84,0x9D,0xD5,0x25,0x53,0xF7,0x8F,
0x10,0x65,0xB4,0x1D,0x54,0xA0,0xB0,0x23,0xA0,0x4C,0x46,0x35,0x08,0x04,0xEE,0xB4,0xC1,
0x10,0x7C,0x84,0xF3,0x9F,0xDA,0x18,0x68,0x74,0xEB,0x79,0x5A,0xF6,0x04,0x65,0xE3,0xEF,
0x10,0x52,0x9D,0x5B,0x6E,0xB9,0xF5,0x49,0x56,0xB5,0x2D,0xCE,0x9C,0x8D,0xC0,0xF3,0x77,
0x10,0xD8,0xD9,0x70,0x67,0x9A,0x9A,0x65,0x95,0x85,0xB4,0xEE,0x9D,0x2E,0xC8,0xD9,0xC0,
0x10,0x1B,0x56,0x8B,0x0F,0xCE,0x8A,0xD4,0x5F,0x93,0x7D,0x64,0xD1,0xC9,0x08,0xBD,0x0A,
0x10,0x7B,0x1D,0xC4,0xF5,0x9F,0x33,0xD1,0xBF,0xD3,0x58,0x71,0x69,0xF9,0x2C,0x33,0xCD,
0x10,0x54,0xBE,0x47,0x47,0x4B,0x85,0xB6,0xE7,0xAE,0x71,0xD9,0x05,0x65,0xEB,0x2D,0x89,
0x10,0x98,0x6C,0xC6,0x6C,0x77,0x45,0x76,0x23,0x8B,0x68,0x3B,0x08,0xF8,0x6B,0xED,0x9F,
0x10,0x5C,0x3C,0xC8,0x50,0x76,0xA0,0xBE,0x84,0x07,0xAD,0xE7,0x5B,0x9F,0xDF,0x46,0xC1,
0x10,0xEA,0xAF,0xBE,0x93,0x13,0x22,0x33,0x3B,0xCB,0x02,0x8F,0x35,0x71,0x43,0x2A,0xA6,
0x10,0xE4,0x80,0x8E,0x2B,0xEC,0xD0,0x9F,0x58,0x21,0xD0,0xCF,0x65,0x0C,0x3C,0x37,0xED,
0x10,0x9C,0xDD,0x81,0xA6,0x48,0x58,0x60,0x61,0xE3,0xFF,0xAE,0xC6,0xB3,0x71,0xDB,0x33,
0x10,0xC5,0x25,0x11,0x5B,0x77,0xA7,0x13,0x76,0xDA,0xD9,0x10,0xD6,0xBE,0x89,0x0A,0x39,
0x10,0x63,0x22,0xE4,0x4C,0x36,0x6A,0x16,0xD2,0x02,0x15,0xBA,0xA4,0x42,0xE9,0x0D,0x2B,
0x10,0xE6,0x4D,0x95,0x63,0x82,0x88,0x2C,0xFE,0xC3,0xF4,0xE0,0xE2,0xCC,0x2E,0x01,0x40,
0x10,0xCB,0xF7,0xBC,0x23,0xFD,0xDA,0xD8,0x48,0x5C,0xB2,0x75,0x22,0x48,0x51,0x1F,0x0C,
0x10,0x2D,0x4D,0xA2,0x32,0xD0,0x24,0x73,0x46,0xAD,0x70,0xC4,0xE6,0x6B,0x38,0x66,0x3D,
0x10,0x83,0xB4,0x09,0xA2,0x5B,0xE3,0x7A,0xB0,0x87,0xCD,0x64,0x8D,0x78,0xAA,0x21,0xEE,
0x10,0x17,0x82,0x0D,0x80,0x3E,0x53,0x11,0xAC,0x58,0xFC,0xDF,0xE7,0xA9,0xC5,0x27,0xC5,
0x10,0xC0,0x45,0xE3,0x9D,0x41,0x60,0xF7,0xBA,0xE0,0x11,0xBF,0x81,0x50,0x95,0x5A,0x95,
0x10,0x35,0xBA,0xEF,0x85,0x8A,0xF2,0x3E,0x61,0xA2,0xC9,0x4E,0x53,0xFD,0x25,0x4A,0x06,
0x10,0xB8,0xFF,0x4B,0xA2,0xE2,0x25,0xDD,0x59,0x73,0x7C,0xEC,0x5E,0x4F,0xAC,0xD9,0x9B,
0x10,0xA7,0xAB,0xA5,0x8F,0xE4,0xA3,0xBA,0x75,0xFE,0x57,0x1F,0x49,0x69,0x12,0xA3,0xD8,
0x10,0x55,0xBA,0x32,0x5E,0xFC,0x48,0x9A,0x05,0x26,0x4D,0xF6,0xB8,0x52,0x90,0x8A,0x0F,
0x10,0x66,0x1F,0x70,0x65,0x5F,0xEA,0xCC,0xE4,0xAE,0x77,0xBF,0xE3,0x74,0x8E,0xF0,0xFC,
0x10,0xBF,0x31,0x36,0x39,0x55,0xD4,0xA7,0xE5,0x42,0x3B,0x3D,0x4B,0xCC,0x6B,0x7B,0x02,
0x10,0x54,0x54,0xC4,0xC8,0xC5,0x8A,0x34,0x1C,0x0D,0xB8,0x71,0x0B,0xF1,0xB4,0xDC,0x02,
0x10,0x04,0x64,0x9A,0x7A,0xBE,0xFE,0xD0,0x62,0x12,0x09,0xF2,0xFA,0x40,0xFD,0x06,0x85,
0x10,0x66,0xD1,0x04,0xD3,0xD8,0xBE,0x0F,0x4A,0x5F,0xEE,0x6B,0x97,0xE5,0xCE,0x98,0x25,
0x10,0x6A,0x33,0xF5,0xCA,0x22,0xBF,0x1F,0x6E,0x83,0x1E,0xE9,0xDB,0x75,0x22,0xE4,0x6E,
0x10,0xB0,0x37,0xB4,0x46,0xBE,0xD3,0xE7,0x03,0x1F,0x9E,0xD1,0x8F,0x53,0x37,0xFA,0x0D,
0x10,0x61,0xB0,0x73,0x9D,0x8B,0xBD,0x9A,0x8B,0xFE,0x26,0x78,0x94,0x1B,0x36,0x2A,0xC5,
0x10,0xCC,0x7F,0x16,0x8E,0x53,0x8A,0x25,0x34,0x1D,0xA8,0xDD,0x02,0xFD,0x78,0xD4,0x35,
0x10,0xBE,0xA3,0x41,0x61,0x75,0x8A,0x54,0x47,0x6F,0x86,0x7E,0x70,0xBF,0xF4,0xA5,0xDC,
0x10,0x6F,0x24,0xDD,0x98,0xDF,0x5C,0x8E,0xCE,0x36,0xD4,0x0B,0xC9,0xF0,0x7B,0x2A,0xCC,
0x10,0xA0,0x63,0xA5,0x09,0x4D,0xF0,0x84,0x7E,0x7A,0x9D,0xA0,0x83,0xD5,0x03,0x21,0x5F,
0x10,0xAC,0x52,0xB4,0x89,0x80,0x7C,0x87,0xB5,0xC0,0x81,0xAC,0xDB,0xA4,0xE2,0x79,0x72,
0x10,0x96,0xDE,0x15,0x8C,0x4A,0x8D,0xCA,0x30,0x12,0x1B,0x0C,0x0C,0x52,0xCC,0x7D,0x29,
0x10,0xB2,0x49,0x48,0x9F,0x5E,0xF6,0xD0,0x4C,0x8C,0x48,0x0A,0x98,0x11,0x3E,0x5E,0x36,
0x10,0x48,0xC9,0xF7,0xB5,0x9C,0xB8,0x06,0x80,0x9B,0xAE,0x14,0x4E,0xD8,0x0A,0x0F,0x76,
0x10,0xCE,0x4F,0x3C,0x39,0x7C,0x77,0x2F,0x5F,0xFC,0xC0,0x98,0xDD,0x8B,0x76,0x81,0x71,
0x10,0x5F,0xC7,0x3C,0x49,0x61,0xE2,0x0A,0xEF,0x0B,0x63,0xC2,0x42,0x1A,0x4A,0x43,0xAD,
0x10,0xA5,0xDD,0x49,0x09,0xFF,0x65,0xCE,0x98,0x76,0xB4,0x3B,0xA9,0xD1,0xD6,0x3A,0xA0,
0x10,0x1D,0x16,0x11,0xC4,0x8E,0x03,0x40,0x25,0x42,0x85,0x1A,0xA6,0x37,0xB1,0xDB,0x70,
0x10,0x1B,0x39,0xEB,0xB7,0x86,0xCA,0x8E,0xB1,0x47,0xE6,0xC7,0xFB,0x91,0xA1,0xF8,0x23,
0x10,0xE5,0x18,0xFD,0xF1,0x0B,0xE9,0x6F,0x41,0x35,0xCF,0xD8,0x9D,0x27,0x01,0x80,0x6E,
0x10,0xDF,0xE3,0x9D,0xF0,0xF3,0x65,0x9D,0xE3,0xCA,0x84,0x0A,0xCD,0xE8,0x07,0x68,0x12,
0x10,0x5D,0xD9,0x4D,0xF5,0xD7,0x93,0x7C,0xA1,0x8E,0xE9,0x10,0x6C,0x8E,0xC2,0x1C,0xDE,
0x10,0xB1,0x5E,0x81,0x4A,0xCF,0x7D,0x6C,0x78,0x82,0x84,0x8C,0xE4,0xDB,0x45,0x4B,0xF2,
0x10,0x00,0x48,0x73,0x63,0xED,0xD6,0x4E,0x48,0xB8,0x00,0x59,0x7E,0xF4,0x4E,0x92,0x42,
0x10,0xB1,0x07,0xBA,0x05,0x8A,0x4B,0x55,0xC0,0x39,0x45,0x31,0x6F,0x40,0x8A,0xD0,0x35,
0x10,0x72,0x7C,0xA3,0x10,0xCE,0x34,0xB3,0xDF,0xA2,0xAE,0xD6,0x3D,0xEE,0x86,0xB5,0x0F,
0x10,0xD3,0xD7,0x9B,0xCC,0x9F,0xCC,0x8E,0x32,0x54,0x0A,0xF7,0x25,0x2B,0xB4,0x89,0xDF,
0x10,0xE1,0x8C,0x01,0x05,0x16,0xB9,0x9E,0x3A,0xEB,0xEB,0x04,0xAB,0x98,0xCF,0xC3,0x86,
0x10,0x12,0x00,0xF4,0xE0,0x0D,0x11,0xBC,0x6B,0x4F,0x95,0xF5,0x41,0x73,0xD7,0x23,0x3A,
0x10,0x93,0x24,0x96,0x02,0x4F,0x2E,0x13,0x27,0xD3,0xE2,0xDE,0xA1,0x6F,0x8D,0xE9,0x27,
0x10,0x3F,0x34,0x82,0x7C,0x91,0x5B,0x94,0x1F,0xE3,0xE3,0x97,0x7D,0x9C,0x5D,0xCB,0x14,
0x10,0x9D,0x37,0x80,0x80,0x50,0x76,0x20,0xC2,0xB8,0xE4,0x43,0x5E,0xEC,0x7A,0x9B,0x28,
0x10,0xEB,0xF8,0x0E,0x92,0xF1,0x0C,0xF7,0x76,0x30,0x54,0xAC,0x8E,0x90,0xA1,0x6A,0x8B,
0x10,0xDE,0x2C,0x01,0xA3,0x72,0x51,0x83,0xFC,0xE6,0xA4,0x58,0x72,0x1F,0xBF,0xD2,0xB7,
0x10,0x44,0xC0,0xE6,0x93,0x89,0x9F,0x0E,0xF5,0x83,0x22,0x0E,0xA3,0x1A,0xDD,0x51,0x62,
0x10,0xAB,0x12,0x22,0xDC,0x24,0x88,0xF7,0x04,0x3A,0x3B,0x9A,0x71,0x82,0x0E,0x68,0xDE,
0x10,0xDD,0x03,0x81,0xA7,0x73,0x05,0xC4,0x44,0xE6,0x29,0xC0,0x66,0xF1,0x53,0x6F,0x03,
0x10,0x1B,0x3B,0xA0,0x23,0x8E,0xD5,0xC3,0x6F,0xCD,0xA0,0xF4,0xA7,0xE8,0x7A,0xAC,0xEB,
0x10,0x9E,0x1E,0xC5,0x80,0x0A,0xF9,0xE9,0x52,0x65,0xBE,0x96,0x22,0x14,0x1F,0x41,0x76,
0x10,0x38,0x42,0x80,0xBD,0xF6,0x6F,0x3C,0x44,0xA3,0x9C,0xA5,0x16,0x7F,0x1C,0xD0,0x5D,
0x10,0xB9,0xDF,0xDD,0x44,0xE6,0x3D,0x6E,0xC3,0x82,0xB9,0x5F,0xD7,0x34,0xDB,0xBC,0x6B,
0x10,0x40,0x20,0x62,0x70,0xD7,0xA9,0x8B,0x2F,0x94,0x0C,0x59,0xAB,0xFB,0xBF,0x96,0x34,
0x10,0x19,0x01,0x0B,0xE5,0x1B,0xDC,0x30,0xB7,0xEA,0x72,0xC8,0xBE,0xED,0x62,0x92,0xB7,
0x10,0x51,0x7A,0x3E,0xB3,0xD5,0x16,0xFC,0x11,0xDC,0xD1,0xA4,0xF7,0xCB,0x08,0xC6,0xE6,
0x10,0x8D,0x9A,0x06,0x65,0xCF,0xDC,0x12,0xD3,0xFA,0x4D,0xB6,0x5C,0xAC,0x24,0x81,0x82,
0x10,0xB0,0x71,0xC1,0xCF,0x25,0xA6,0xB2,0x24,0xCA,0x79,0x6D,0xA0,0x2F,0x98,0x4C,0x5A,
0x10,0xF5,0x74,0x5D,0x57,0x7C,0xD5,0x75,0x88,0x2A,0x3D,0xC2,0x7A,0x79,0xA6,0x90,0x3E,
0x10,0xEA,0x32,0xDC,0x79,0x01,0x8C,0x82,0x24,0x51,0x1B,0x00,0xED,0x2D,0x46,0x88,0xC8,
0x10,0xC2,0x6A,0x87,0xF9,0x64,0xF2,0xAF,0x24,0x38,0x82,0xE9,0xD7,0xAB,0x87,0x5A,0xC5,
0x10,0x37,0x80,0x76,0x6E,0x14,0x24,0x01,0xDA,0xB3,0x84,0x81,0x09,0xF0,0x87,0xC6,0x1D,
0x10,0x59,0x34,0x76,0xA5,0x71,0x62,0x55,0xAE,0xE1,0xFF,0xDB,0xB9,0x21,0x14,0xAF,0xC4,
0x10,0x08,0x2D,0x76,0x16,0x54,0x6D,0x20,0x18,0x57,0xA5,0x63,0x73,0x70,0xD5,0x92,0x53,
0x10,0x77,0x33,0x22,0x06,0x50,0x8B,0xD4,0xBD,0x18,0x83,0x5C,0xA3,0x4C,0x2C,0xF3,0xF2,
0x10,0x0A,0x13,0xE2,0xB6,0x4E,0x9C,0x11,0xC1,0xC8,0x0D,0x5E,0xEF,0x4F,0x78,0xC0,0xE7,
0x10,0x02,0xEA,0x43,0x24,0x7A,0xF2,0x43,0x4C,0xF7,0xD7,0x16,0xBD,0x60,0xC2,0xDF,0xD4,
0x10,0x72,0xB9,0x1B,0x20,0x8C,0xAB,0xC7,0x94,0xC8,0x61,0x17,0x6F,0xA5,0x27,0x86,0x50,
0x10,0x60,0xA3,0x2B,0xA0,0xB5,0x25,0x9E,0xE8,0x69,0x95,0x2F,0x83,0x54,0x06,0xCC,0x89,
0x10,0x1E,0xA0,0xCC,0x2B,0xBB,0xAC,0xC1,0x49,0x00,0x0E,0xDE,0x04,0xAB,0x7A,0x18,0x08,
0x10,0x17,0xC0,0xC9,0x27,0xB4,0xD2,0xD7,0xAD,0xF9,0x15,0x83,0xC0,0xC2,0x7B,0x87,0x65,
0x10,0x74,0x50,0x7C,0x5E,0x50,0x57,0x11,0xE3,0x27,0xCE,0xF6,0x2B,0x9B,0x6D,0xF2,0x5D,
0x10,0xCA,0x0F,0x1C,0x2F,0x20,0x80,0x78,0x94,0x35,0xF0,0xDA,0x8D,0xF3,0xCA,0xF0,0x78,
0x10,0x1E,0x1A,0xD1,0xF3,0x65,0x12,0xBB,0x12,0x92,0xD2,0x08,0xBF,0xA8,0xF5,0xEE,0x11,
0x10,0x9F,0xFF,0x0A,0x3B,0x92,0x45,0x65,0xC5,0x6B,0x29,0xD4,0xB9,0xED,0x9D,0x04,0xDB,
0x10,0xA7,0xBC,0x50,0xA4,0xB6,0x84,0x01,0x87,0xC1,0x63,0x21,0x4E,0x59,0xD7,0xA0,0x0C,
0x10,0xB7,0x4A,0x01,0x6F,0x72,0x39,0x7C,0x11,0x88,0xC2,0x80,0x10,0xBD,0xAE,0x4E,0xD7,
0x10,0xDC,0xBF,0x80,0xE9,0xD1,0xAD,0x1A,0x63,0x03,0x52,0x95,0xF8,0x01,0x7C,0x45,0x3F,
0x10,0x5F,0xB2,0x91,0x48,0x27,0x7B,0xFE,0xA5,0xEF,0x60,0xB3,0xAC,0xAC,0x94,0x7B,0xAB,
0x10,0x2E,0xC1,0x76,0x69,0x33,0xE4,0x0D,0xFD,0x1D,0x5C,0xC9,0x4B,0x6F,0x0A,0xEE,0xD4,
0x10,0x07,0xA4,0x07,0xBA,0xD7,0x57,0x24,0xE2,0x9D,0xFA,0xD9,0x5A,0xD6,0x23,0x91,0x16,
0x10,0x3B,0xA7,0x60,0x49,0xCE,0xDA,0xE0,0x51,0xFD,0x34,0x8A,0xA0,0x31,0xFC,0xC6,0x57,
0x10,0xB4,0xF1,0x49,0x8E,0xC8,0xE6,0xAE,0x3D,0x55,0x78,0x3F,0x86,0x27,0xC2,0x22,0xE1,
0x10,0x70,0x93,0x8F,0x1C,0x89,0xD5,0x35,0xBD,0x45,0xC8,0xBB,0x71,0xAC,0xA8,0xE0,0x0F,
0x10,0x63,0x1C,0x6C,0x79,0xEF,0xE8,0xB9,0x5D,0xD5,0xCB,0x6A,0xF5,0xA9,0x33,0x26,0x27,
0x10,0xFE,0x77,0xA4,0xDF,0x40,0xDF,0xF3,0x89,0x76,0x3D,0x65,0x1E,0xA3,0xEF,0x51,0x86,
0x10,0xAE,0xB9,0xBC,0x8C,0x2D,0xC2,0x74,0x52,0xBD,0xEC,0x78,0xD3,0x1F,0xC5,0x4E,0x47,
0x10,0xDE,0x1C,0x7D,0x2E,0xBB,0x1B,0x79,0xDF,0x30,0xC3,0xA2,0x39,0xBE,0x43,0xD1,0xDB,
0x10,0x27,0xAF,0xA9,0x80,0xAE,0x0A,0xBC,0xEF,0xD3,0x44,0x7A,0xDB,0xB6,0x36,0x9E,0xCF,
0x10,0x62,0x6D,0xB6,0xD5,0xE0,0x5E,0xFE,0x47,0xFD,0xDC,0xDE,0xF8,0x83,0xB7,0x4A,0xCB,
0x10,0xED,0x08,0x70,0xC1,0x12,0x0B,0xAA,0x56,0x81,0x18,0xB1,0x86,0x51,0x60,0x91,0x5D,
0x10,0x18,0x31,0x71,0xF8,0x46,0x88,0x41,0xBB,0xE2,0xFC,0x1E,0x15,0xE9,0x9B,0x75,0x02,
0x10,0xD1,0x1F,0xAC,0x18,0xB2,0x0A,0xEC,0xBC,0x03,0x3D,0x32,0xEC,0xFD,0xD9,0xD4,0x96,
0x10,0xC8,0xB2,0xEE,0x87,0xB3,0xF7,0x7C,0x6A,0x8D,0xF5,0xF7,0x54,0x1B,0xB7,0x0F,0xE8,
0x10,0xA0,0xD3,0xE9,0x01,0xB5,0x33,0x58,0x90,0x87,0xEB,0xE5,0xA9,0x27,0xE5,0xAC,0x05,
0x10,0x7B,0xDA,0xCF,0xE3,0xB7,0x8E,0x5C,0x6A,0xE8,0xD0,0x59,0xD5,0x97,0x25,0x55,0x75,
0x10,0x7B,0xAE,0x4F,0xC6,0x8B,0x28,0xEC,0xCF,0xF7,0x9B,0xBB,0x2A,0x33,0xE1,0x30,0xF7,
0x10,0x41,0x04,0xCC,0x54,0xB1,0x2F,0xEC,0x7A,0x70,0x9E,0x4E,0x7E,0x7C,0xF2,0xD2,0x5B,
0x10,0x8B,0x30,0x03,0xD7,0x04,0x2B,0x26,0xA4,0x6C,0x66,0x68,0x7D,0xED,0x54,0x9B,0xF5,
0x10,0xF1,0xE0,0x78,0xC5,0xFD,0xE0,0x39,0x3E,0xA8,0x66,0x1D,0x4B,0x86,0x2B,0x1E,0xA6,
0x10,0x56,0x8E,0xFB,0x0C,0x40,0x4A,0xC0,0x04,0x88,0x4D,0xE0,0x90,0x6E,0x48,0x57,0x55,
0x10,0x61,0xB3,0x11,0x23,0x68,0x55,0x2E,0xF0,0x11,0x0A,0xF9,0xB7,0xE4,0x2B,0x69,0x10,
0x10,0x7D,0x3B,0x3A,0xAE,0xCC,0x5F,0x00,0xBF,0xE3,0x78,0xF4,0x69,0xA9,0x61,0x37,0xA2,
0x10,0x77,0x4C,0xC3,0xA4,0x7A,0xC1,0xA8,0x37,0x67,0x1E,0x3A,0x34,0xAA,0x0B,0x0C,0x5A,
0x10,0x79,0x35,0xE0,0x9F,0xCB,0x18,0x10,0x2C,0x0A,0x75,0xA1,0xAE,0xF2,0x9C,0x90,0x0C,
0x10,0x36,0xEF,0x3F,0xC7,0x9B,0x5C,0xE5,0x2E,0xCB,0xC7,0xA3,0x7B,0x21,0xB0,0x7A,0x47,
0x10,0xEF,0xF4,0x2B,0x78,0x6D,0x3B,0xA6,0x22,0x95,0xF0,0x95,0xA9,0x82,0x07,0x4A,0x76,
0x10,0xB4,0x5D,0xFE,0x73,0x4F,0x5A,0x0E,0xE6,0xD3,0x28,0x2E,0x0F,0x9C,0x7D,0x9D,0x1A,
0x10,0x00,0x80,0x58,0xDE,0x0C,0x75,0xDB,0x3D,0x82,0xCF,0x32,0xE8,0xE9,0x62,0x10,0x68,
0x10,0xC1,0x2E,0xD9,0x6F,0x96,0xF8,0x9E,0x0C,0x62,0xC7,0x52,0x73,0x86,0x1B,0x67,0x71,
0x10,0x3A,0x65,0x1F,0x48,0xDE,0x1D,0xF0,0x09,0xF6,0x75,0x2F,0xEF,0xE8,0xE1,0xED,0x07,
0x10,0xD2,0x0D,0x01,0x62,0xFF,0x9A,0xEC,0x28,0x9B,0x31,0xA3,0x4D,0x45,0x19,0xBB,0xF9,
0x10,0xF4,0xF7,0x58,0x01,0x3E,0xAA,0xA2,0x0D,0x02,0xCC,0x6C,0xDE,0x5A,0xAA,0x5C,0x6E,
0x10,0x29,0x33,0x4F,0xF3,0x4B,0xAE,0x35,0x1A,0x6F,0x20,0xB1,0x19,0x8A,0x51,0x88,0x11,
0x10,0x8B,0xDF,0xEE,0x29,0xB7,0x33,0xB4,0x1E,0x11,0x47,0x22,0x6A,0x53,0x97,0x1E,0xD4,
0x10,0x76,0xC9,0x91,0x95,0x83,0x78,0x1E,0xA5,0x55,0xB0,0x73,0xFF,0xFD,0x5D,0xDE,0xA4,
0x10,0x25,0x7A,0x5F,0x6C,0x42,0xD2,0x8C,0x9C,0x48,0x8A,0x87,0x32,0xB0,0x36,0x3D,0xC1,
0x10,0x7C,0x29,0xA7,0xB2,0x28,0xA7,0x10,0xE8,0xCB,0x68,0xA6,0xE2,0xA2,0x74,0x75,0x08,
0x10,0x30,0x23,0x60,0x7A,0x11,0x99,0x01,0xAB,0x29,0x7D,0xCC,0xBB,0x2F,0x2A,0x59,0xDC,
0x10,0x3C,0x16,0xDF,0xCC,0x27,0x94,0x48,0x0E,0x40,0xCE,0x5F,0xA9,0x8E,0x9D,0x29,0x3F,
0x10,0x1B,0xC5,0x50,0xA1,0x43,0x9B,0xC0,0x59,0x66,0xAD,0xC4,0xCF,0x53,0xCB,0xA6,0xE3,
0x10,0xB2,0x45,0xBB,0xE7,0x45,0xA3,0xDE,0xCF,0x87,0x0D,0x5A,0xA8,0x67,0x21,0x05,0x6A,
0x10,0x6B,0x7F,0x87,0x4A,0x5A,0xC1,0x68,0x77,0x62,0xB0,0xA3,0xDC,0x73,0xF2,0x9D,0xCF,
0x10,0x16,0x94,0x39,0xDC,0xF8,0xBF,0x6D,0x56,0xE2,0x9F,0x00,0x61,0x09,0x3B,0x90,0x30,
0x10,0x5A,0xCE,0x0D,0xBA,0xBD,0x15,0x64,0xF4,0xDE,0x20,0x7A,0x9F,0x3D,0x03,0xAA,0x9C,
0x10,0xBE,0xC4,0x05,0x39,0xE4,0x04,0xD7,0xA1,0xFA,0x8E,0x34,0x31,0x15,0xAF,0x32,0x35,
0x10,0x29,0x0A,0xC5,0xFF,0x99,0xE3,0xE0,0x48,0x0B,0xBE,0x20,0x5E,0x00,0x27,0x39,0x7E,
0x10,0x71,0x58,0xED,0x83,0xBF,0x64,0xE4,0x71,0x13,0x0E,0x64,0xCB,0x24,0xD2,0x64,0xA1,
0x10,0x01,0x35,0x85,0x51,0x92,0x0D,0x1C,0x8E,0xC2,0xF2,0x73,0xAB,0x15,0xCC,0x50,0xF8,
0x10,0x4B,0x0D,0xA4,0xC4,0x55,0x91,0xCD,0x76,0xB3,0xF0,0xF3,0xAD,0x64,0x22,0xA6,0x4B,
0x10,0x0C,0x07,0xB9,0x55,0x57,0x86,0xA5,0xB3,0x0B,0xD6,0x46,0xFC,0x1A,0x0A,0xF6,0xFE,
0x10,0x2C,0xF6,0x57,0xEE,0xF5,0x14,0xDA,0x22,0xDF,0xD1,0x64,0x82,0x3E,0x5C,0xFC,0xC0,
0x10,0x97,0x8B,0x3F,0x5E,0xE7,0xC5,0x6D,0xA2,0xAA,0x48,0xC1,0x0A,0x08,0x4F,0x20,0xF2,
0x10,0x7F,0xB8,0x7E,0xF2,0x3A,0xF5,0xF0,0xD5,0x55,0xE6,0x12,0x62,0xFA,0xDF,0x40,0xE0,
0x10,0xF0,0xA2,0x9E,0x3A,0xCE,0x26,0xFC,0x83,0xAF,0x0E,0xC2,0x2D,0x7D,0x9E,0xC6,0xED,
0x10,0x28,0x6B,0xFE,0x64,0x37,0x9F,0xBE,0x29,0x56,0x82,0x1F,0x7B,0x5E,0xFB,0xC0,0x0E,
0x10,0x64,0x9B,0xD4,0x75,0x96,0x75,0xE5,0xC3,0xB8,0x2D,0x59,0xA2,0xED,0xA0,0xCD,0x3B,
0x10,0xD8,0xB6,0x31,0x96,0x3D,0xB5,0x3C,0x24,0xF5,0x26,0x41,0xDF,0x17,0x52,0x8E,0x6F,
0x10,0x72,0x26,0xCD,0xA5,0xF4,0xBE,0x6D,0xCA,0x05,0x31,0x4B,0x57,0xA2,0x62,0xE2,0x24,
0x10,0xD6,0x75,0x09,0xC5,0xB5,0x6E,0xF4,0x44,0x57,0x5D,0x7A,0x78,0xBE,0x30,0x44,0xD2,
0x10,0x06,0x95,0x38,0xC9,0xF1,0xD0,0xB3,0x46,0x62,0xEE,0x93,0x93,0x0D,0x40,0x93,0x0A,
0x10,0xAB,0x38,0xF7,0xCC,0xB5,0x45,0x0B,0xD3,0x74,0xAF,0xD8,0x28,0x39,0x80,0x6E,0x5E,
0x10,0xB4,0x48,0x5C,0xFD,0xAE,0x1A,0x8A,0xE0,0xCD,0x22,0x31,0x25,0x5F,0x78,0xD6,0xFC,
0x10,0xDB,0xE6,0xA1,0xD1,0xDC,0xBD,0x9D,0x5A,0xF0,0x45,0x16,0x3E,0x0D,0x9D,0x1B,0xA6,
0x10,0x69,0xF2,0xFC,0xA8,0xA4,0xB9,0xAD,0xBB,0x94,0x9A,0x3F,0x6C,0x49,0xDB,0x2E,0xD1,
0x10,0xF9,0x7B,0x21,0x9D,0xE2,0x06,0x27,0xA3,0xDD,0x52,0x92,0x1A,0x46,0xD6,0xB7,0xF3,
0x10,0xE8,0xC3,0xE8,0xE0,0xAB,0xF4,0x3A,0xC0,0xF3,0x49,0x01,0x32,0xD8,0x82,0x17,0xFE,
0x10,0xCD,0x13,0xEB,0xD0,0x50,0xDB,0xB5,0x5E,0xC4,0x8A,0xF2,0x55,0x74,0x97,0xF3,0x15,
0x10,0x20,0xB9,0x9C,0xF0,0xB8,0x01,0x60,0x02,0xB5,0x48,0x98,0x62,0x9F,0x20,0xCF,0xEC,
0x10,0x6D,0x01,0x30,0xA1,0x73,0x3A,0xB1,0xC3,0x00,0x5D,0x93,0xFD,0x91,0x47,0x5F,0xF6,
0x10,0x68,0x9E,0x01,0xC7,0xE6,0x7D,0xFA,0xB7,0x6B,0x84,0x86,0x52,0xAE,0x45,0x1B,0x23,
0x10,0xE5,0xE1,0x2A,0xA2,0x73,0x28,0x60,0xEE,0xDE,0x3D,0x73,0x70,0xB7,0xFD,0x50,0xAE,
0x10,0x1E,0x4E,0x7A,0x21,0x38,0x5E,0x12,0xC3,0x31,0x6F,0x6A,0x4D,0xC0,0x6E,0xB6,0x44,
0x10,0x80,0x7D,0x46,0x7F,0x10,0x07,0x1D,0xD8,0x59,0x16,0x56,0x5A,0x9A,0xCA,0xC2,0x09,
0x10,0x44,0x77,0xA5,0xD9,0xBF,0x44,0xD0,0xA8,0x22,0xB9,0x12,0x7D,0xA0,0x03,0xE3,0x4B,
0x10,0xD9,0x77,0xC9,0x20,0xCD,0x72,0x46,0x55,0xB4,0x17,0x6D,0x9F,0xAB,0x03,0xC0,0x4D,
0x10,0x00,0x04,0xDF,0x46,0xD1,0xD6,0x5A,0x5F,0xD9,0x1D,0x41,0x23,0xA7,0x21,0x8B,0x76,
0x10,0xC5,0xC7,0x22,0x8E,0x3B,0x24,0xAF,0x09,0x81,0x16,0x78,0x3E,0x6C,0xF8,0xE3,0x0C,
0x10,0x25,0x7D,0xF2,0xE3,0x55,0xD0,0xFB,0xE0,0xA9,0xDE,0x0F,0xC8,0x06,0xFC,0x61,0x28,
0x10,0x31,0xF4,0x7B,0x00,0x72,0xFA,0xFF,0x73,0x3E,0xB8,0x74,0xA7,0x91,0x6C,0xEF,0xA8,
0x10,0xB9,0x58,0xBD,0x1D,0xC6,0x23,0xB6,0x6B,0x6A,0x4B,0xA6,0x20,0x0C,0x01,0xF4,0x67,
0x10,0x60,0x0F,0x65,0xF4,0x07,0x0E,0x1A,0x6E,0x83,0xF7,0x33,0x64,0x1E,0xC6,0xDD,0xA0,
0x10,0x38,0x6D,0x47,0xFA,0xD7,0x34,0x5E,0x19,0x1D,0xC7,0x4D,0x49,0xFD,0xF3,0xF0,0xCD,
0x10,0x7F,0x2E,0xAB,0x5F,0xBC,0x01,0xC9,0x1E,0x3A,0x62,0x04,0x6E,0x85,0x33,0xD9,0x23,
0x10,0x2B,0xA2,0xB6,0x26,0x7C,0x86,0xB4,0xF3,0x98,0x0F,0xD7,0xDC,0xF4,0x03,0x19,0x99,
0x10,0xDA,0x1A,0xCC,0x36,0xF6,0xA2,0xEA,0x9B,0x3F,0xB9,0xC4,0xB7,0xFE,0xA5,0x2D,0x93,
0x10,0xBC,0xA7,0x16,0x0B,0x0C,0x97,0xFD,0x8F,0xAD,0x08,0xF0,0x55,0x0C,0x99,0x88,0xD3,
0x10,0x13,0x92,0x4D,0x33,0xBF,0xA9,0x00,0x93,0x1F,0x93,0x51,0xA6,0x02,0x82,0x2F,0x3B,
0x10,0x26,0x29,0x49,0x24,0x6C,0x9A,0x82,0x2C,0x12,0x37,0xE1,0xBB,0xC8,0xEC,0x24,0xE4,
0x10,0xEC,0x90,0x77,0x3A,0x7A,0xDB,0x08,0xC0,0x18,0x13,0xF5,0xE0,0x58,0xB0,0x8D,0xC7,
0x10,0x61,0x62,0x18,0x87,0x3B,0xC7,0x27,0x3D,0x56,0x49,0xF2,0x46,0x68,0x6D,0x29,0xDD,
0x10,0x6E,0xA8,0x95,0xDE,0x55,0x76,0x8A,0xB9,0x0A,0x45,0xD5,0xD7,0x55,0x82,0x38,0x3E,
0x10,0xBC,0x08,0x1E,0x6F,0xE1,0x43,0x83,0x17,0xE9,0x08,0x3F,0xA8,0xF0,0x50,0xE7,0x4A,
0x10,0xFA,0xEA,0x63,0xEA,0x0D,0xD9,0x6A,0xA4,0x29,0x4C,0x65,0x7E,0x35,0x39,0x07,0x34,
0x10,0x56,0x6A,0x53,0xD3,0x30,0x9E,0x12,0x15,0x65,0x04,0x49,0x4A,0xD0,0x80,0xAD,0xB7,
0x10,0x8A,0x9F,0x1A,0x7A,0xF5,0xA2,0x39,0x64,0x0B,0xC3,0xAD,0x05,0xA5,0x86,0x9B,0x22,
0x10,0xAB,0x1C,0x6E,0xC6,0x95,0x99,0x4E,0x4E,0xB4,0x24,0x43,0x96,0x2C,0x4D,0x56,0x08,
0x10,0x4B,0x95,0x0D,0x95,0x64,0xFF,0xD6,0x37,0x73,0xA1,0x03,0x9C,0xC3,0xE9,0x60,0x09,
0x10,0x38,0x4C,0xAE,0xDE,0xAC,0xAC,0x89,0x59,0x6E,0xE7,0xEC,0xBA,0x75,0x97,0x75,0xED,
0x10,0xCA,0xF8,0x9B,0x71,0x64,0xC1,0xA0,0xFA,0x03,0x50,0xFE,0x86,0x4F,0xC5,0xFB,0x62,
0x10,0x07,0x9B,0x0F,0x11,0x00,0x85,0x40,0x3D,0x19,0xF5,0x96,0xC2,0xA0,0x42,0x96,0x97,
0x10,0x6A,0xC6,0xEE,0x50,0x93,0xD4,0xC8,0x69,0x17,0x0E,0xBE,0xA8,0x7D,0x89,0xF2,0x9E,
0x10,0x2E,0xAB,0x10,0x2D,0x5F,0x28,0x54,0xCC,0x3B,0xDB,0xDF,0x9E,0x67,0x8C,0x82,0x07,
0x10,0xF1,0xCE,0x80,0x19,0xDE,0xB1,0xDD,0x02,0xD3,0x84,0xCA,0x4A,0xD2,0x68,0x0A,0x6A,
0x10,0xF5,0x2D,0x58,0xDA,0xC2,0x6E,0x29,0x6F,0x31,0x0B,0xA8,0x71,0x65,0xEC,0xFA,0xA6,
0x10,0xBF,0xB4,0xE6,0x36,0xAB,0xA6,0x32,0x29,0x37,0xF0,0x49,0xEF,0x3F,0x29,0x33,0x0E,
0x10,0xF4,0x98,0x68,0x48,0x11,0xF0,0x17,0x98,0x99,0xB8,0xB8,0xC9,0xA2,0x9E,0x82,0xF0,
0x10,0xC4,0xCA,0xA1,0x35,0xA5,0x92,0xFB,0x7B,0x10,0x1D,0xFE,0xC8,0x8E,0x6C,0x7E,0xE2,
0x10,0x6E,0xA4,0x05,0x52,0xF5,0xD8,0xFF,0x27,0xD0,0x0F,0xC2,0x0C,0xF2,0x73,0xA6,0x07,
0x10,0x71,0x3C,0xE9,0x25,0x98,0x87,0x96,0xE5,0x9B,0xB9,0x83,0x59,0x14,0xCD,0xD4,0xEF,
0x10,0xE3,0x83,0x93,0x52,0x01,0xE8,0x47,0x95,0x4D,0x6D,0x88,0x9D,0xA6,0x62,0xD7,0xB4,
0x10,0x34,0x13,0xA5,0xDA,0xFB,0x24,0xEE,0xFF,0x80,0xD9,0x63,0xA6,0x56,0x5D,0xAE,0x9E,
0x10,0x4F,0x55,0x48,0x1F,0x3B,0x4A,0xDC,0x19,0x8E,0x44,0xA5,0xE1,0x4E,0x9E,0x20,0x50,
0x10,0xF0,0xB6,0x31,0xD1,0x2A,0x02,0x37,0x61,0xE2,0xE9,0xD7,0xAD,0xB9,0x7B,0x97,0xC7,
0x10,0xDE,0x8D,0x63,0x2A,0xF1,0x4B,0x5B,0xD2,0xEB,0xB3,0xBC,0x1B,0x83,0xD0,0x7F,0x98,
0x10,0x13,0xCE,0x6F,0xB5,0xB8,0x4B,0xB5,0xAB,0x2D,0xA5,0xEF,0x76,0x45,0xF1,0x3D,0x0C,
0x10,0x24,0x47,0xFB,0x16,0x32,0xF0,0x1B,0xB8,0x32,0xDD,0xA8,0x27,0x00,0xF7,0xAC,0x61,
0x10,0x35,0x84,0x40,0xEF,0x5A,0xF9,0x9B,0xC1,0x51,0x1C,0xA4,0xEF,0xBA,0xB5,0x49,0x19,
0x10,0xCD,0xE7,0x9B,0xB9,0x20,0x5C,0x9C,0x29,0x5B,0x77,0x78,0x56,0xC5,0x0A,0x35,0xB5,
0x10,0x45,0xAE,0x00,0x06,0x7C,0xA0,0x56,0x9A,0xB9,0x6F,0xF8,0x7B,0xFB,0x85,0xB0,0x26,
0x10,0x96,0x35,0xF5,0x64,0xC8,0x11,0xC5,0x92,0xF7,0x4A,0x14,0x9F,0x27,0x8F,0xCD,0xA9,
0x10,0xF1,0xE2,0x0B,0x7E,0xB3,0x4A,0x8C,0x06,0xB7,0xE5,0x74,0x23,0x1E,0x99,0x3B,0xF5,
0x10,0x17,0x2E,0x01,0x85,0xC0,0x5B,0x5B,0x7A,0xAE,0x33,0xA1,0xD4,0xCB,0x12,0x93,0xC1,
0x10,0x54,0xB4,0xF7,0x3A,0xA6,0x28,0xC2,0x22,0x55,0xC6,0x0B,0x33,0x87,0x92,0xC5,0x32,
0x10,0x42,0xE7,0xB7,0x1B,0x65,0xAA,0x98,0x6B,0xD3,0xE9,0xCB,0x34,0x58,0x1E,0x1F,0xE8,
0x10,0x39,0xA9,0xE3,0xC7,0x8F,0x16,0x09,0xC0,0x31,0x6A,0x50,0xF9,0x4A,0xE4,0x8C,0x0E,
0x10,0xF2,0x1B,0x4C,0x23,0x69,0x95,0xFE,0x98,0x7F,0xCF,0xE3,0x56,0xE2,0xF7,0xC6,0x31,
0x10,0x10,0xE3,0xDF,0x94,0x29,0x7E,0x69,0xD0,0xBE,0x8E,0x51,0x8C,0xF6,0x98,0xE2,0x9B,
0x10,0x74,0xE2,0x5D,0xE8,0x2D,0x38,0x28,0xCC,0x28,0xFC,0x78,0x42,0x6A,0xC5,0xF1,0x59,
0x10,0xDE,0x69,0xFD,0x86,0x04,0xE7,0x1E,0x41,0x8C,0x4A,0xB6,0x68,0x42,0xF3,0xC3,0xFA,
0x10,0xAF,0xE9,0x98,0xF2,0xE3,0x0B,0xB4,0x26,0x99,0xDB,0xE3,0x04,0x1D,0x77,0x7B,0xDB,
0x10,0xB0,0x95,0xF0,0x7C,0xD4,0xCF,0xD8,0xF5,0x6B,0xC5,0xF7,0xE5,0xDE,0x1D,0x0B,0x2A,
0x10,0xED,0x5F,0xC8,0x41,0x63,0xB3,0x3B,0x68,0x8E,0x3C,0x6F,0xE0,0xA3,0xC8,0xFF,0xE0,
0x10,0x72,0x10,0xD4,0x3A,0x71,0xC3,0xFC,0x79,0x7D,0x18,0xAA,0x67,0xD7,0x5E,0x7D,0xFA,
0x10,0xE0,0xE5,0x5D,0xB9,0xDA,0xE1,0x67,0x01,0x40,0x52,0xD1,0xB1,0xEF,0xCC,0xAE,0xF9,
0x10,0x39,0x81,0xE7,0xD5,0x46,0xBD,0x85,0x2E,0x20,0x0C,0x58,0x51,0xD3,0x0A,0xEB,0x93,
0x10,0xC2,0x23,0x67,0xAD,0xDD,0x29,0x4A,0x04,0x63,0x4F,0x70,0xFF,0xC7,0x3C,0x64,0xB0,
0x10,0xDE,0xF6,0xEE,0x10,0x58,0xF2,0xD9,0x19,0x42,0xC7,0xE4,0x92,0x2F,0xF8,0xB6,0x47,
0x10,0x8E,0xAF,0x95,0xD7,0x9A,0x0A,0x12,0xA2,0xE7,0xA9,0x58,0x58,0xA4,0x24,0x12,0x38,
0x10,0x01,0x1D,0xE5,0xB9,0xD5,0x0A,0x6C,0x2D,0xAE,0x52,0x78,0x89,0x00,0xE8,0xE0,0x19,
0x10,0x24,0x2D,0xFC,0x81,0x84,0x49,0xDD,0x24,0x71,0x4D,0xA7,0xAD,0x5E,0x3A,0x9E,0x79,
0x10,0x0B,0x4E,0x6B,0xEC,0x07,0x0C,0x9F,0x84,0xE7,0x7B,0xCA,0x80,0xAE,0x7B,0x39,0x9E,
0x10,0xBA,0x49,0x39,0xB7,0xF1,0x15,0x6F,0x3F,0x17,0xC8,0xE0,0xDA,0x62,0x2C,0x6A,0x2C,
0x10,0x91,0xCD,0xEC,0xE0,0x7C,0x5B,0xAD,0x7D,0xF5,0x86,0xCB,0x94,0x9D,0x9C,0x52,0xDC,
0x10,0xD2,0x3F,0x7E,0x1D,0x3B,0xD5,0x3A,0xB4,0xEC,0xB0,0xEB,0xE7,0x82,0x2E,0x7B,0x85,
0x10,0xAE,0x10,0x40,0x27,0x6D,0x7D,0xDE,0x41,0x82,0x21,0x27,0x20,0x0B,0x3B,0x8D,0x9B,
0x10,0xB8,0x8B,0xD6,0x07,0x25,0xCF,0xC6,0x8D,0xA4,0x9F,0x41,0xF1,0x89,0x9B,0xCA,0xFA,
0x10,0x64,0x81,0x63,0x73,0x2F,0x2F,0x11,0x5D,0x32,0x3D,0x71,0x7E,0xDD,0x06,0xC0,0x0C,
0x10,0xCB,0x34,0x81,0x48,0x81,0x66,0xE0,0xAD,0xBD,0x3A,0x00,0x8B,0xCF,0x8D,0xEF,0xA4,
0x10,0xFC,0xD4,0x67,0xE9,0xED,0xDC,0x45,0x2A,0x59,0x2F,0xEE,0xC2,0xDB,0x5A,0x07,0xD0,
0x10,0x66,0x0E,0x66,0x81,0xC3,0x30,0xB4,0xE3,0x7F,0x8B,0xBD,0xB4,0xDA,0x34,0xEE,0xEE,
0x10,0xFE,0x2D,0x71,0x3A,0x39,0x5A,0xED,0xE5,0xF9,0xEB,0xE5,0xB1,0x0C,0x53,0x2A,0x37,
0x10,0xCF,0x04,0xF9,0xFE,0x7C,0xD3,0x5A,0x68,0x57,0x0B,0x54,0x98,0x48,0x8D,0xDB,0x80,
0x10,0xE9,0x78,0xB7,0x14,0x45,0x4C,0xA3,0xA2,0x0C,0x11,0xDB,0x02,0x06,0xEB,0xA6,0xA6,
0x10,0x03,0x63,0x41,0xD9,0xCB,0xE5,0x8A,0xA5,0xF2,0xFB,0xCA,0xF9,0x92,0x4D,0x75,0xF8,
0x10,0xB7,0x10,0x78,0x5D,0x45,0x7D,0x75,0x6A,0xE6,0xFD,0x8E,0xC2,0x5F,0x7A,0xCA,0x03,
0x10,0x97,0x97,0x61,0x79,0x9F,0x4F,0x8F,0xEF,0x45,0x07,0xBB,0x7E,0xFE,0xB3,0x1A,0xA7,
0x10,0x87,0x33,0x61,0x71,0x3A,0x74,0x6D,0x98,0xA0,0xB0,0x47,0xA6,0x07,0x03,0x41,0x45,
0x10,0x09,0xB1,0x0A,0x45,0x3E,0x5F,0xAA,0x6E,0xCB,0xD8,0xDA,0x4D,0x83,0xE2,0x6B,0x13,
0x10,0xA0,0x61,0xA3,0xC0,0xF9,0x10,0x8E,0x01,0x1E,0xAD,0xD7,0xB9,0x6B,0xC1,0x69,0x79,
0x10,0x3D,0x36,0x45,0xEA,0x48,0x19,0x46,0xDC,0x54,0xF7,0x65,0x28,0x70,0x08,0x06,0xA8,
0x10,0x82,0xA5,0x7B,0xDE,0xD4,0x2C,0x97,0x0D,0xE0,0xCC,0x6D,0x1B,0x57,0xE5,0xCA,0x60,
0x10,0xCA,0x8A,0xBD,0x39,0xAA,0xA9,0x91,0x5E,0x8E,0x12,0x84,0x2E,0xCD,0xFA,0xD3,0x5E,
0x10,0xE6,0x15,0xB8,0x53,0x4A,0x89,0xB3,0x0E,0xBF,0x3F,0x90,0x1B,0x9A,0x9E,0x32,0x6C,
0x10,0xAF,0xE3,0x35,0xE1,0x57,0x3D,0x66,0x1C,0x5F,0xD6,0xA2,0x83,0x33,0xEE,0xE5,0x14,
0x10,0xF1,0x99,0xF6,0xB4,0x7D,0x8C,0x67,0xA2,0xC8,0xFB,0x26,0x09,0x40,0xC1,0x37,0x4F,
0x10,0x73,0x97,0xE7,0x43,0x4B,0xE2,0xEB,0x8F,0x20,0x55,0x50,0xFF,0x65,0xFF,0x1E,0x45,
0x10,0x5B,0xF8,0xFD,0x87,0x08,0x6A,0xA4,0x75,0x1A,0xF6,0x18,0x44,0x37,0xE4,0xF5,0xEB,
0x10,0x0A,0x69,0xED,0x64,0xC5,0x82,0xF6,0x19,0x06,0x31,0xC2,0xCD,0x1A,0x5D,0x01,0xB7,
0x10,0x67,0x6E,0x1D,0xCD,0x38,0xDF,0xCE,0x56,0xE8,0xC9,0x66,0xED,0x2D,0xD1,0x20,0xE1,
0x10,0xB8,0x6D,0xA8,0x8B,0xB9,0x9E,0x14,0x10,0xFE,0x3A,0xCA,0xBA,0x5C,0xD6,0x02,0xA9,
0x10,0xDE,0x2C,0xC4,0xB4,0xCE,0x31,0x91,0x81,0x50,0xCA,0x6F,0x36,0x55,0x08,0xC4,0x5F,
0x10,0xE9,0x98,0xA6,0x67,0x09,0x07,0x0C,0x7A,0xC0,0x41,0xAE,0x20,0xF9,0x41,0x25,0xA6,
0x10,0x0D,0xD7,0x78,0x08,0xF8,0xB9,0xE3,0x72,0xD6,0x6F,0xB2,0x4C,0x33,0x8A,0x4D,0xC7,
0x10,0x7D,0x95,0x33,0xC3,0x44,0xE3,0x92,0xDA,0x33,0xA5,0x4B,0x88,0xA1,0x53,0x85,0x2E,
0x10,0xC2,0x7D,0x19,0x1E,0x9C,0x40,0xA9,0x09,0xED,0xFA,0xD5,0x91,0xFD,0x8A,0xC4,0xBD,
0x10,0x25,0x23,0x43,0xB7,0x07,0x94,0x89,0xA9,0x7C,0xEB,0x2E,0x47,0x38,0x00,0xEC,0x6A,
0x10,0x5B,0x8B,0xA9,0x60,0xEF,0xCD,0x4A,0x2A,0xA5,0x40,0xA5,0x40,0x04,0x01,0xFA,0x48,
0x10,0xA1,0x71,0xC6,0xA2,0x79,0x76,0x5D,0x74,0x0C,0x17,0x05,0x1C,0x97,0xED,0x15,0x37,
0x10,0x61,0xE5,0x9F,0xDA,0x91,0x40,0x4A,0x7F,0x85,0x71,0x29,0x62,0x1B,0x56,0x89,0x23,
0x10,0x9F,0xC1,0xBB,0x32,0x5A,0x3B,0xAE,0x5F,0xC2,0x3A,0x90,0xAD,0x36,0x4A,0x36,0xB5,
0x10,0xB3,0x25,0xDB,0x78,0x5D,0x24,0xD7,0x20,0x37,0xA4,0xC9,0x01,0x29,0x41,0xE3,0x20,
0x10,0x3A,0xC1,0x6D,0xD8,0x3C,0xB9,0xCB,0x54,0x69,0xE6,0x65,0xA3,0xE2,0x61,0xF7,0x7A,
0x10,0x35,0xED,0xB6,0xE6,0x4F,0x82,0x20,0x30,0x6F,0x11,0x56,0xB1,0x9B,0xBF,0xFD,0x1F,
0x10,0xF0,0x7A,0xF5,0x10,0x3F,0x33,0x64,0xEE,0xDF,0x46,0x94,0x5A,0xDB,0xFC,0x02,0xB4,
0x10,0x7F,0xC6,0x4B,0xAF,0x4D,0xCD,0x06,0xBA,0x5B,0x70,0xD4,0xAD,0x90,0xBB,0x7E,0x71,
0x10,0x19,0x5C,0x62,0xF0,0xD9,0xDE,0xBC,0x3C,0x61,0x7F,0x50,0x65,0x2D,0x0A,0x72,0x88,
0x10,0x69,0xF4,0xD5,0xDA,0x1F,0x2B,0x65,0x9A,0xDD,0x01,0x0A,0x30,0xC0,0x56,0x20,0x01,
0x10,0x27,0xCD,0xDD,0xF4,0x73,0xBF,0x87,0x58,0x4F,0x6D,0x52,0x12,0xDC,0xD7,0x25,0xCD,
0x10,0x3D,0xB1,0x77,0x78,0x61,0x06,0x6B,0x63,0xC5,0xCC,0x9A,0x36,0xB5,0x3A,0xF9,0xC6,
0x10,0xDF,0x28,0x58,0x38,0xD9,0x62,0x98,0x7E,0x25,0x4E,0x6F,0xD0,0xBF,0x6D,0x20,0x1D,
0x10,0x78,0x5C,0xF3,0xAD,0x39,0x2E,0xB4,0xDD,0xCD,0xFC,0xF2,0x9C,0x66,0xEF,0xC4,0x46,
0x10,0x23,0x47,0x39,0xDF,0x6B,0x78,0x6F,0xB5,0xC2,0xE0,0xB2,0xE4,0x02,0x1C,0xAC,0x26,
0x10,0xB6,0xEA,0xEF,0xDD,0xEB,0xE9,0x04,0x39,0xEE,0x93,0xD6,0x7A,0xF2,0xE4,0x26,0xDB,
0x10,0x42,0xBB,0x0C,0xDB,0x8D,0x02,0xF2,0x07,0x7A,0xED,0xCC,0x32,0xFE,0xEB,0x12,0x8D,
0x10,0x7B,0x47,0x5B,0xCF,0x36,0x4A,0xB2,0x90,0xAE,0xAE,0xC3,0x46,0xD7,0x7E,0x67,0xD9,
0x10,0x0D,0x88,0x22,0x74,0x42,0x90,0x80,0x24,0xBA,0x20,0xE0,0xC2,0x20,0xAC,0xD1,0x90,
0x10,0x5E,0x18,0x70,0x5C,0xAE,0x52,0xA5,0x6B,0xC5,0x0F,0x7E,0xFF,0x86,0x91,0x26,0x09,
0x10,0x84,0xA9,0x8A,0xB6,0xAC,0xFA,0x84,0x6C,0x5C,0x4F,0x1F,0x45,0x10,0x61,0xE8,0x0A,
0x10,0x5B,0x95,0x05,0x1F,0xFC,0xD7,0x72,0xA9,0x70,0xAE,0x1D,0x7F,0xE3,0xF6,0xC1,0xBF,
0x10,0x64,0xA1,0x11,0x1C,0x54,0xD5,0x64,0x78,0x8C,0x5A,0x9E,0x39,0xEC,0x7F,0xCF,0x27,
0x10,0x95,0x38,0x52,0xE4,0xF2,0xEC,0x11,0x26,0x35,0x26,0x2F,0x86,0x76,0xFD,0x70,0x4B,
0x10,0x97,0xAC,0x7E,0x05,0x5B,0x19,0x31,0x48,0x1F,0xD3,0x13,0x0B,0xCC,0xAE,0x2A,0xC2,
0x10,0x9E,0x79,0x55,0x8A,0x96,0xE2,0x02,0x06,0x04,0x8F,0x2F,0x32,0x2B,0x6D,0xD8,0x40,
0x10,0x72,0xE3,0x32,0x0D,0xEE,0xB2,0xC1,0x31,0x1A,0x25,0xCF,0x65,0x03,0x3F,0x68,0x6D,
0x10,0xBD,0x48,0x3D,0xB1,0x7E,0xA2,0xFC,0xC6,0xFD,0x58,0xB6,0x79,0x20,0x8B,0x69,0xA0,
0x10,0x2B,0xE5,0xB9,0x62,0x3A,0xE3,0x5D,0x26,0x9D,0xF9,0xA5,0x8B,0x13,0x6B,0xC8,0x18,
0x10,0xA1,0x1C,0xF3,0xDE,0x2B,0xA7,0x5E,0x98,0x5C,0x19,0xDF,0x31,0x65,0x79,0xDE,0x53,
0x10,0xAA,0x49,0xE7,0xD5,0xC9,0x70,0x81,0x37,0xC1,0xA3,0xB8,0xCD,0x7B,0x79,0xA0,0x72,
0x10,0xA1,0x7B,0xF4,0xC7,0xF2,0x95,0x4D,0xC8,0x6A,0xC7,0x24,0x39,0x42,0xD3,0xBE,0xD0,
0x10,0x25,0xED,0xBE,0x90,0xD4,0x77,0x1B,0x2E,0xDF,0xF3,0x18,0x42,0x46,0xC4,0x9F,0x4E,
0x10,0xF5,0xD9,0x37,0xA1,0xC3,0xEC,0x1F,0xFC,0x06,0x7C,0x3D,0xBF,0xCB,0xAE,0xB8,0x33,
0x10,0x57,0x5A,0xB7,0x6D,0x90,0x18,0x27,0xEA,0x66,0x5B,0xD5,0xAB,0xBD,0x1C,0x1D,0xBC,
0x10,0x85,0x7F,0xDE,0xCF,0xDD,0xE0,0xD7,0x94,0xF2,0xF4,0x1D,0xDC,0x4F,0x60,0xE6,0xC8,
0x10,0x30,0xE8,0x8E,0xB7,0xFD,0xC8,0xFC,0x6E,0x1A,0xB0,0x63,0x1A,0xF7,0x77,0x6D,0x7D,
0x10,0x51,0x51,0x25,0x5F,0xB6,0x93,0x34,0x4C,0x9C,0x6A,0x1A,0x96,0x7C,0xB5,0xAF,0x2F,
0x10,0x26,0x0C,0xB9,0x6F,0x9E,0xDB,0x7A,0x67,0xEC,0xF0,0xD4,0x3A,0xE5,0x08,0x04,0x1F,
0x10,0x40,0x11,0x98,0x86,0x53,0x34,0xE2,0xB2,0xED,0xB5,0x08,0xD0,0x90,0x2B,0x91,0x23,
0x10,0x75,0xF2,0x8B,0xC1,0xF0,0x16,0xD4,0xA4,0xEC,0x23,0xB9,0x0B,0xD1,0xA3,0xE3,0x9D,
0x10,0x54,0xD5,0xEB,0x41,0x86,0xA5,0x16,0x95,0x39,0x98,0xB4,0x6B,0xEF,0xAF,0x17,0x64,
0x10,0x9C,0xED,0x8C,0x9E,0x86,0x39,0x28,0x18,0x06,0x50,0x66,0xBC,0xB5,0x63,0xC9,0xDE,
0x10,0x2A,0x7F,0xD0,0xFA,0x61,0x47,0x71,0xDA,0xEA,0x85,0x97,0xED,0xA5,0xEC,0x59,0x23,
0x10,0x44,0xAD,0xF1,0xEA,0xD9,0x44,0xE6,0x7F,0x73,0xF5,0xAE,0x1C,0x7D,0x6E,0x6E,0x40,
0x10,0x4F,0xF9,0xCC,0x44,0xD4,0x53,0xD2,0x4A,0x65,0x0B,0x82,0x31,0x07,0x26,0x44,0xB5,
0x0D,0x42,0x96,0xC7,0x24,0x28,0x6F,0x9D,0xED,0x9B,0x85,0x9C,0x9B,0x3F,
0
};
volatile uint16_t dist;  // Ensure the compiler doesn't optimize this variable

/* USER CODE END PV */

void SystemClock_Config(void);
static void MX_GPIO_Init(void);
static void MX_USART2_UART_Init(void);
static void MX_I2C1_Init(void);
static void MX_ADC1_Init(void);
static void MX_TIM3_Init(void);

/* USER CODE BEGIN 0 */
void write_register(uint8_t reg_addr, uint8_t value) {
    HAL_I2C_Mem_Write(&hi2c1, TMF8801_ADDR, reg_addr, I2C_MEMADD_SIZE_8BIT, &value, 1, 100);
    HAL_Delay(5);
}

uint8_t read_register(uint8_t reg_addr) {
    uint8_t value = 0xFF;
    HAL_I2C_Mem_Read(&hi2c1, TMF8801_ADDR, reg_addr, I2C_MEMADD_SIZE_8BIT, &value, 1, 100);
    return value;
}

bool waitForCpuReady() {
    uint8_t val = 0;
    for (uint16_t i = 0; i < 100; i++) {
        HAL_I2C_Mem_Read(&hi2c1, TMF8801_ADDR, 0xE0, I2C_MEMADD_SIZE_8BIT, &val, 1, 100);
        if ((val & 0x01)) return true;
        HAL_Delay(5);
    }
    return false;
}

void remap_rst_RAM()
{
uint8_t cmd_buf[3]={0x11,0x00,0xEE};
int ready=-1,x=0,y=0;
//write_register(0x02,0x80);
HAL_I2C_Mem_Write(&hi2c1, TMF8801_ADDR, 0x08, I2C_MEMADD_SIZE_8BIT, cmd_buf,3, 100);
HAL_Delay(10);
//printf("reset RAM oknr");
//TMF8801_reset();
while(1){
y++;
if (!waitForCpuReady() && y%10==0)
{
x=read_register(0xE0);
printf("CPU staute= %#x not ready wait~nr",x);
//HAL_Delay(10);
}
else if(y>50)
{ printf("Ram reset failnr",x);
for(;;);}
else if(waitForCpuReady())
{printf("Ram reset oknr");
return;}
}
}

uint8_t TMF8801_CalcChecksum(uint8_t *data, uint8_t len) {
    uint8_t sum = 0;
    for (uint8_t i = 0; i < len; i++) sum += data[i];
    return sum ^ 0xFF;
}

bool TMF8801_ReadStatusACK() {
	uint8_t status[3] = {0};
	HAL_I2C_Mem_Read(&hi2c1, TMF8801_ADDR, 0x08, I2C_MEMADD_SIZE_8BIT, status, 3, 100);
	printf("Status response: %02X %02X %02X\r\n", status[0], status[1], status[2]);
	if (status[0] == 0x00 && status[1] == 0x00 && status[2] == 0xFF) {
	    return true;
	}
	return false;

}

uint8_t TMF8801_GetAppId() {
    uint8_t id = 0;
    HAL_I2C_Mem_Read(&hi2c1, TMF8801_ADDR, 0x00, I2C_MEMADD_SIZE_8BIT, &id, 1, 100);
    return id;
}

bool TMF8801_LoadBootloader() {
    uint8_t regValue = 0x80;
    write_register(APPREQID, regValue);
    for (int i = 0; i < 100; i++) {
        HAL_Delay(5);
        if (read_register(APPID) == 0x80) return true;
    }
    return false;
}
bool TMF8801_WaitForApplication() {
    for (int i = 0; i < 100; i++) {
        HAL_Delay(5);
        if (read_register(APPID) == 0xC0) return true;
    }
    printf("Timeout: App0 did not start (AppID != 0xC0)\r\n");
    return false;
}

bool TMF8801_LoadApplication() {
    uint8_t regValue = 0xC0;
    write_register(APPREQID, regValue);
    HAL_Delay(5);
    return TMF8801_WaitForApplication();
}

void TMF8801_reset() {
    uint8_t val = 0x80;
    HAL_I2C_Mem_Write(&hi2c1, TMF8801_ADDR, 0xE0, I2C_MEMADD_SIZE_8BIT, &val, 1, 100);
}

int __tmf8801_status_read()
{
    uint8_t status = 0;
    HAL_I2C_Mem_Read(&hi2c1, TMF8801_ADDR, 0x10, I2C_MEMADD_SIZE_8BIT, &status, 1, 100);
    if (status == TMF8x01_OK)
        return TMF8x01_OK;
    else
        return TMF8x01_NK;
}

void reset_SW() {
    uint8_t status = 0, x = 0, cmd_buf[3] = {0x10, 0x00, 0xEF}, ready = -1;

    write_register(APPREQID, Bootloader);
    TMF8801_reset();

    if (!waitForCpuReady()) {
        x = read_register(0xE0);
        printf("CPU status = %#x not ready\r\n", x);
        return;
    }

    while (1) {
        status = (read_register(APPID) == Bootloader) ? 1 : 0;
        if (status == 1) {  // Bootloader is running
            HAL_I2C_Mem_Write(&hi2c1, TMF8801_ADDR, 0x08, I2C_MEMADD_SIZE_8BIT, cmd_buf, 3, 100);
            HAL_Delay(10);

            ready = __tmf8801_status_read();
            if (ready == TMF8x01_OK) {
                printf("reset SW ok\r\n");
                return;
            } else if (ready == TMF8x01_NK) {
                printf("reset SW failed\r\n");
                for (;;);
            }
        }
    }
}

bool TMF8801_DownloadRamPatch() {
    uint8_t buf[20] = {0};
    const uint8_t *addr = tmf8801_initBuf;
    uint8_t flag = 0;

    if (TMF8801_GetAppId() != 0x80 && !TMF8801_LoadBootloader()) return false;

    // Send DOWNLOAD_INIT command
    uint8_t cmd1[] = {0x14, 0x01, 0x29, 0xC1};
    HAL_I2C_Mem_Write(&hi2c1, TMF8801_ADDR, 0x08, I2C_MEMADD_SIZE_8BIT, cmd1, sizeof(cmd1), 100);
    HAL_Delay(10);
    if (!TMF8801_ReadStatusACK())
    	return false;

    // Set up RAM address pointer (ADDR_RAM = 0x43 0x02 0x00 0x00)
    uint8_t addr_cmd[] = {0x43, 0x02, 0x00, 0x00, 0xBA};
    HAL_I2C_Mem_Write(&hi2c1, TMF8801_ADDR, 0x08, I2C_MEMADD_SIZE_8BIT, addr_cmd, sizeof(addr_cmd), 100);
    HAL_Delay(10);

    if (!TMF8801_ReadStatusACK())
    	return false;

    // Begin sending W_RAM data blocks
    buf[0] = 0x08;
    buf[1] = 0x41;
    while ((flag = *addr++) > 0) {
        buf[2] = flag;
        memcpy(&buf[3], addr, flag);
        addr += flag;
        buf[3 + flag] = TMF8801_CalcChecksum(&buf[1], flag + 2);
        HAL_I2C_Mem_Write(&hi2c1, TMF8801_ADDR, buf[0], I2C_MEMADD_SIZE_8BIT, &buf[1], 3 + flag, 100);
        HAL_Delay(5);
        if (!TMF8801_ReadStatusACK())
        	return false;
    }

    // Send RAMREMAP_RESET command
    uint8_t reset[] = {0x11, 0x00, 0xEE};
    HAL_I2C_Mem_Write(&hi2c1, TMF8801_ADDR, 0x08, I2C_MEMADD_SIZE_8BIT, reset, sizeof(reset), 100);
    HAL_Delay(10);
    return waitForCpuReady();
};

void TMF8801_FactoryCalib() {
    if (read_register(ID) != 0x07) {
        printf("TMF8801 not detected. ID mismatch.\r\n");
        return;
    }
//    TMF8801_LoadApplication();
        if (!TMF8801_WaitForApplication()) {
            uint8_t z = read_register(APPID);
            printf("Application status = %#x error", z);
            return;
        }
    write_register(COMMAND, FACTORY_CALIB);

    uint32_t timeout = HAL_GetTick() + 2000;
    uint8_t appId = read_register(APPID);
    printf("Current AppID = %#x\r\n", appId);  // Should be 0x41

    while (HAL_GetTick() < timeout) {
        if (read_register(0x1E) == 0x0A) {
            HAL_I2C_Mem_Read(&hi2c1, TMF8801_ADDR, FACTORY_CALIB_0, I2C_MEMADD_SIZE_8BIT, factory_calib_data, 14, 100);
            printf("Factory calibration complete.\r\n");
            return;
        }
        HAL_Delay(20);
    }

    printf("Factory calibration timeout!\r\n");
}

void sensor_init() {
	write_register(COMMAND, DOWNLOAD_CALIB_AND_STATE);  // 0x0B

	// Write factory calibration data
	HAL_I2C_Mem_Write(&hi2c1, TMF8801_ADDR, FACTORY_CALIB_0, I2C_MEMADD_SIZE_8BIT, factory_calib_data, 14, 100);
	HAL_I2C_Mem_Write(&hi2c1, TMF8801_ADDR, STATE_DATA_WR_0, I2C_MEMADD_SIZE_8BIT, algo_state_data, 11, 100);
	// Set distance measurement config
	write_register(CMD_DATA7, 0x03);
	write_register(CMD_DATA6, 0x23);  // mode
	write_register(CMD_DATA5, 0x00);
	write_register(CMD_DATA4, 0x00);
	write_register(CMD_DATA3, 0x00);
	write_register(CMD_DATA2, 0x64); // e.g., 100 ms
	write_register(CMD_DATA1, 0xD8);
	write_register(CMD_DATA0, 0x04);  // trigger measurement

	// Start distance measurement
	write_register(COMMAND, DISTANCE_MEASURE_MODE);  // 0x02

}

unsigned int TMF8801_distancePeak_mm() {
	uint8_t int_status = 0;

	    // Read INT_STATUS register
	    HAL_I2C_Mem_Read(&hi2c1,TMF8801_ADDR , 0xE1, 1, &int_status, 1, HAL_MAX_DELAY);

	    if ((int_status & 0x01) == 0) {
	        return -1; // No new result
	    }

	    // Read distance result from result registers
	    uint8_t dist[2];
	    HAL_I2C_Mem_Read(&hi2c1, TMF8801_ADDR, 0x22, 1, dist, 2, HAL_MAX_DELAY);
	    int distance = (dist[1] << 8) | dist[0];

	    // Clear the int1 status
	    uint8_t clear = 0x01;
	    HAL_I2C_Mem_Write(&hi2c1, TMF8801_ADDR, 0xE1, 1, &clear, 1, HAL_MAX_DELAY);

	    return distance;

}
/* USER CODE END 0 */

int main(void)
{

  /* MCU Configuration--------------------------------------------------------*/

  /* Reset of all peripherals, Initializes the Flash interface and the Systick. */
  HAL_Init();

  /* Configure the system clock */
  SystemClock_Config();

  /* Initialize all configured peripherals */
  MX_GPIO_Init();
  MX_USART2_UART_Init();
  MX_I2C1_Init();
  MX_ADC1_Init();
  MX_TIM3_Init();

  reset_SW();
  TMF8801_DownloadRamPatch();
  HAL_Delay(20);
  remap_rst_RAM();
  uint8_t appid = read_register(0x00);
  printf("AppID after RAM remap = %#x\r\n", appid);
  TMF8801_FactoryCalib();
  sensor_init();
  /* USER CODE END 2 */

  /* Infinite loop */
  /* USER CODE BEGIN WHILE */
  while (1)
  {
	  uint16_t distance = TMF8801_distancePeak_mm();
	  dist=distance;
	  HAL_Delay(100);
    /* USER CODE END WHILE */

  }
}

void SystemClock_Config(void)
{
  RCC_OscInitTypeDef RCC_OscInitStruct = {0};
  RCC_ClkInitTypeDef RCC_ClkInitStruct = {0};

  /** Configure the main internal regulator output voltage
  */
  if (HAL_PWREx_ControlVoltageScaling(PWR_REGULATOR_VOLTAGE_SCALE1) != HAL_OK)
  {
    Error_Handler();
  }

  /** Initializes the RCC Oscillators according to the specified parameters
  * in the RCC_OscInitTypeDef structure.
  */
  RCC_OscInitStruct.OscillatorType = RCC_OSCILLATORTYPE_HSI;
  RCC_OscInitStruct.HSIState = RCC_HSI_ON;
  RCC_OscInitStruct.HSICalibrationValue = RCC_HSICALIBRATION_DEFAULT;
  RCC_OscInitStruct.PLL.PLLState = RCC_PLL_ON;
  RCC_OscInitStruct.PLL.PLLSource = RCC_PLLSOURCE_HSI;
  RCC_OscInitStruct.PLL.PLLM = 1;
  RCC_OscInitStruct.PLL.PLLN = 10;
  RCC_OscInitStruct.PLL.PLLP = RCC_PLLP_DIV7;
  RCC_OscInitStruct.PLL.PLLQ = RCC_PLLQ_DIV2;
  RCC_OscInitStruct.PLL.PLLR = RCC_PLLR_DIV2;
  if (HAL_RCC_OscConfig(&RCC_OscInitStruct) != HAL_OK)
  {
    Error_Handler();
  }

  /** Initializes the CPU, AHB and APB buses clocks
  */
  RCC_ClkInitStruct.ClockType = RCC_CLOCKTYPE_HCLK|RCC_CLOCKTYPE_SYSCLK
                              |RCC_CLOCKTYPE_PCLK1|RCC_CLOCKTYPE_PCLK2;
  RCC_ClkInitStruct.SYSCLKSource = RCC_SYSCLKSOURCE_PLLCLK;
  RCC_ClkInitStruct.AHBCLKDivider = RCC_SYSCLK_DIV1;
  RCC_ClkInitStruct.APB1CLKDivider = RCC_HCLK_DIV1;
  RCC_ClkInitStruct.APB2CLKDivider = RCC_HCLK_DIV1;

  if (HAL_RCC_ClockConfig(&RCC_ClkInitStruct, FLASH_LATENCY_4) != HAL_OK)
  {
    Error_Handler();
  }
}

static void MX_ADC1_Init(void)
{

  ADC_MultiModeTypeDef multimode = {0};
  ADC_ChannelConfTypeDef sConfig = {0};

  /** Common config
  */
  hadc1.Instance = ADC1;
  hadc1.Init.ClockPrescaler = ADC_CLOCK_ASYNC_DIV1;
  hadc1.Init.Resolution = ADC_RESOLUTION_12B;
  hadc1.Init.DataAlign = ADC_DATAALIGN_RIGHT;
  hadc1.Init.ScanConvMode = ADC_SCAN_DISABLE;
  hadc1.Init.EOCSelection = ADC_EOC_SINGLE_CONV;
  hadc1.Init.LowPowerAutoWait = DISABLE;
  hadc1.Init.ContinuousConvMode = DISABLE;
  hadc1.Init.NbrOfConversion = 1;
  hadc1.Init.DiscontinuousConvMode = DISABLE;
  hadc1.Init.ExternalTrigConv = ADC_SOFTWARE_START;
  hadc1.Init.ExternalTrigConvEdge = ADC_EXTERNALTRIGCONVEDGE_NONE;
  hadc1.Init.DMAContinuousRequests = DISABLE;
  hadc1.Init.Overrun = ADC_OVR_DATA_PRESERVED;
  hadc1.Init.OversamplingMode = DISABLE;
  if (HAL_ADC_Init(&hadc1) != HAL_OK)
  {
    Error_Handler();
  }

  /** Configure the ADC multi-mode
  */
  multimode.Mode = ADC_MODE_INDEPENDENT;
  if (HAL_ADCEx_MultiModeConfigChannel(&hadc1, &multimode) != HAL_OK)
  {
    Error_Handler();
  }

  /** Configure Regular Channel
  */
  sConfig.Channel = ADC_CHANNEL_1;
  sConfig.Rank = ADC_REGULAR_RANK_1;
  sConfig.SamplingTime = ADC_SAMPLETIME_2CYCLES_5;
  sConfig.SingleDiff = ADC_SINGLE_ENDED;
  sConfig.OffsetNumber = ADC_OFFSET_NONE;
  sConfig.Offset = 0;
  if (HAL_ADC_ConfigChannel(&hadc1, &sConfig) != HAL_OK)
  {
    Error_Handler();
  }

}

static void MX_I2C1_Init(void)
{

  hi2c1.Instance = I2C1;
  hi2c1.Init.Timing = 0x10909CEC;
  hi2c1.Init.OwnAddress1 = 0;
  hi2c1.Init.AddressingMode = I2C_ADDRESSINGMODE_7BIT;
  hi2c1.Init.DualAddressMode = I2C_DUALADDRESS_DISABLE;
  hi2c1.Init.OwnAddress2 = 0;
  hi2c1.Init.OwnAddress2Masks = I2C_OA2_NOMASK;
  hi2c1.Init.GeneralCallMode = I2C_GENERALCALL_DISABLE;
  hi2c1.Init.NoStretchMode = I2C_NOSTRETCH_DISABLE;
  if (HAL_I2C_Init(&hi2c1) != HAL_OK)
  {
    Error_Handler();
  }

  /** Configure Analogue filter
  */
  if (HAL_I2CEx_ConfigAnalogFilter(&hi2c1, I2C_ANALOGFILTER_ENABLE) != HAL_OK)
  {
    Error_Handler();
  }

  /** Configure Digital filter
  */
  if (HAL_I2CEx_ConfigDigitalFilter(&hi2c1, 0) != HAL_OK)
  {
    Error_Handler();
  }

}

static void MX_TIM3_Init(void)
{

  TIM_ClockConfigTypeDef sClockSourceConfig = {0};
  TIM_MasterConfigTypeDef sMasterConfig = {0};
  TIM_OC_InitTypeDef sConfigOC = {0};

  htim3.Instance = TIM3;
  htim3.Init.Prescaler = 0;
  htim3.Init.CounterMode = TIM_COUNTERMODE_UP;
  htim3.Init.Period = 65535;
  htim3.Init.ClockDivision = TIM_CLOCKDIVISION_DIV1;
  htim3.Init.AutoReloadPreload = TIM_AUTORELOAD_PRELOAD_ENABLE;
  if (HAL_TIM_Base_Init(&htim3) != HAL_OK)
  {
    Error_Handler();
  }
  sClockSourceConfig.ClockSource = TIM_CLOCKSOURCE_INTERNAL;
  if (HAL_TIM_ConfigClockSource(&htim3, &sClockSourceConfig) != HAL_OK)
  {
    Error_Handler();
  }
  if (HAL_TIM_PWM_Init(&htim3) != HAL_OK)
  {
    Error_Handler();
  }
  sMasterConfig.MasterOutputTrigger = TIM_TRGO_RESET;
  sMasterConfig.MasterSlaveMode = TIM_MASTERSLAVEMODE_DISABLE;
  if (HAL_TIMEx_MasterConfigSynchronization(&htim3, &sMasterConfig) != HAL_OK)
  {
    Error_Handler();
  }
  sConfigOC.OCMode = TIM_OCMODE_PWM1;
  sConfigOC.Pulse = 0;
  sConfigOC.OCPolarity = TIM_OCPOLARITY_HIGH;
  sConfigOC.OCFastMode = TIM_OCFAST_DISABLE;
  if (HAL_TIM_PWM_ConfigChannel(&htim3, &sConfigOC, TIM_CHANNEL_1) != HAL_OK)
  {
    Error_Handler();
  }
  HAL_TIM_MspPostInit(&htim3);

}

static void MX_USART2_UART_Init(void)
{

  huart2.Instance = USART2;
  huart2.Init.BaudRate = 115200;
  huart2.Init.WordLength = UART_WORDLENGTH_8B;
  huart2.Init.StopBits = UART_STOPBITS_1;
  huart2.Init.Parity = UART_PARITY_NONE;
  huart2.Init.Mode = UART_MODE_TX_RX;
  huart2.Init.HwFlowCtl = UART_HWCONTROL_NONE;
  huart2.Init.OverSampling = UART_OVERSAMPLING_16;
  huart2.Init.OneBitSampling = UART_ONE_BIT_SAMPLE_DISABLE;
  huart2.AdvancedInit.AdvFeatureInit = UART_ADVFEATURE_NO_INIT;
  if (HAL_UART_Init(&huart2) != HAL_OK)
  {
    Error_Handler();
  }

}

static void MX_GPIO_Init(void)
{
  GPIO_InitTypeDef GPIO_InitStruct = {0};

  /* GPIO Ports Clock Enable */
  __HAL_RCC_GPIOC_CLK_ENABLE();
  __HAL_RCC_GPIOH_CLK_ENABLE();
  __HAL_RCC_GPIOA_CLK_ENABLE();
  __HAL_RCC_GPIOB_CLK_ENABLE();

  /*Configure GPIO pin Output Level */
  HAL_GPIO_WritePin(GPIOA, GPIO_PIN_4|LD2_Pin, GPIO_PIN_RESET);

  /*Configure GPIO pin : B1_Pin */
  GPIO_InitStruct.Pin = B1_Pin;
  GPIO_InitStruct.Mode = GPIO_MODE_IT_FALLING;
  GPIO_InitStruct.Pull = GPIO_NOPULL;
  HAL_GPIO_Init(B1_GPIO_Port, &GPIO_InitStruct);

  /*Configure GPIO pins : PA4 LD2_Pin */
  GPIO_InitStruct.Pin = GPIO_PIN_4|LD2_Pin;
  GPIO_InitStruct.Mode = GPIO_MODE_OUTPUT_PP;
  GPIO_InitStruct.Pull = GPIO_NOPULL;
  GPIO_InitStruct.Speed = GPIO_SPEED_FREQ_LOW;
  HAL_GPIO_Init(GPIOA, &GPIO_InitStruct);

}

void Error_Handler(void)
{
  __disable_irq();
  while (1)
  {
  }
}
